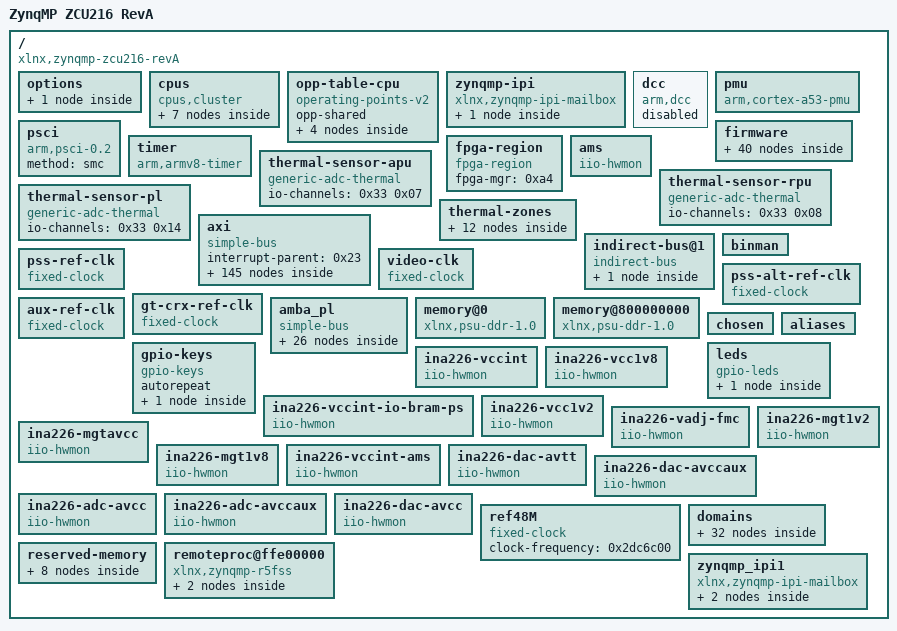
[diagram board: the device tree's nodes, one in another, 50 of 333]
/dts-v1/;

/ {
	compatible = "xlnx,zynqmp-zcu216-revA\0xlnx,zynqmp-zcu216\0xlnx,zynqmp\0ZynqMP ZCU216 RevA\0ZynqMP ZCU216 RevA\0ZynqMP ZCU216 RevA\0ZynqMP ZCU216 RevA\0ZynqMP ZCU216 RevA\0ZynqMP ZCU216 RevA\0ZynqMP ZCU216 RevA\0ZynqMP ZCU216 RevA\0ZynqMP ZCU216 RevA";
	#address-cells = <0x02>;
	#size-cells = <0x02>;
	model = "ZynqMP ZCU216 RevA";
	board = "zcu216";
	device_id = "xczu49dr";
	slrcount = <0x01>;
	family = "ZynqMP";
	speed_grade = "2";

	options {

		u-boot {
			compatible = "u-boot,config";
			bootscr-address = <0x00 0x20000000>;
		};
	};

	cpus {
		#address-cells = <0x01>;
		#size-cells = <0x00>;
		compatible = "cpus,cluster";
		#ranges-address-cells = <0x02>;
		#ranges-size-cells = <0x02>;
		phandle = <0xc7>;

		cpu@0 {
			#cooling-cells = <0x02>;
			compatible = "arm,cortex-a53";
			device_type = "cpu";
			enable-method = "psci";
			operating-points-v2 = <0x82>;
			reg = <0x00>;
			cpu-idle-states = <0x83>;
			next-level-cache = <0x84>;
			clocks = <0x85 0x0a>;
			xlnx,psu-ep = <0x01>;
			xlnx,pss-video-ref-clk-freq = <0x1fc9f08>;
			xlnx,ip-name = "psu_cortexa53";
			xlnx,cpu-1x-clk-freq-hz = <0x00>;
			xlnx,psu-silicon-version = <0x03>;
			cpu-frequency = <0x47865d45>;
			xlnx,cpu-clk-freq-hz = <0x47865d45>;
			xlnx,pss-gt-ref-clk-freq = <0x1fc9f08>;
			xlnx,pss-ref-clk-freq = <0x1fc9f08>;
			bus-handle = <0x01>;
			xlnx,pss-aux-ref-clk-freq = <0x1fc9f08>;
			xlnx,psu-device = "PS8a";
			xlnx,timestamp-clk-freq = <0x5f5dd19>;
			stamp-frequency = <0x5f5dd19>;
			xlnx,pss-alt-ref-clk-freq = <0x1fc9f08>;
			phandle = <0x9a>;
		};

		cpu@1 {
			#cooling-cells = <0x02>;
			compatible = "arm,cortex-a53";
			device_type = "cpu";
			enable-method = "psci";
			reg = <0x01>;
			operating-points-v2 = <0x82>;
			cpu-idle-states = <0x83>;
			next-level-cache = <0x84>;
			xlnx,timestamp-clk-freq = <0x5f5dd19>;
			xlnx,psu-ep = <0x01>;
			xlnx,pss-ref-clk-freq = <0x1fc9f08>;
			stamp-frequency = <0x5f5dd19>;
			xlnx,cpu-1x-clk-freq-hz = <0x00>;
			xlnx,ip-name = "psu_cortexa53";
			xlnx,psu-silicon-version = <0x03>;
			xlnx,psu-device = "PS8a";
			xlnx,cpu-clk-freq-hz = <0x47865d45>;
			bus-handle = <0x01>;
			cpu-frequency = <0x47865d45>;
			phandle = <0x9b>;
		};

		cpu@2 {
			#cooling-cells = <0x02>;
			compatible = "arm,cortex-a53";
			device_type = "cpu";
			enable-method = "psci";
			reg = <0x02>;
			operating-points-v2 = <0x82>;
			cpu-idle-states = <0x83>;
			next-level-cache = <0x84>;
			xlnx,timestamp-clk-freq = <0x5f5dd19>;
			xlnx,psu-ep = <0x01>;
			xlnx,pss-ref-clk-freq = <0x1fc9f08>;
			stamp-frequency = <0x5f5dd19>;
			xlnx,cpu-1x-clk-freq-hz = <0x00>;
			xlnx,ip-name = "psu_cortexa53";
			xlnx,psu-silicon-version = <0x03>;
			xlnx,psu-device = "PS8a";
			xlnx,cpu-clk-freq-hz = <0x47865d45>;
			bus-handle = <0x01>;
			cpu-frequency = <0x47865d45>;
			phandle = <0x9c>;
		};

		cpu@3 {
			#cooling-cells = <0x02>;
			compatible = "arm,cortex-a53";
			device_type = "cpu";
			enable-method = "psci";
			reg = <0x03>;
			operating-points-v2 = <0x82>;
			cpu-idle-states = <0x83>;
			next-level-cache = <0x84>;
			xlnx,timestamp-clk-freq = <0x5f5dd19>;
			xlnx,psu-ep = <0x01>;
			xlnx,pss-ref-clk-freq = <0x1fc9f08>;
			stamp-frequency = <0x5f5dd19>;
			xlnx,cpu-1x-clk-freq-hz = <0x00>;
			xlnx,ip-name = "psu_cortexa53";
			xlnx,psu-silicon-version = <0x03>;
			xlnx,psu-device = "PS8a";
			xlnx,cpu-clk-freq-hz = <0x47865d45>;
			bus-handle = <0x01>;
			cpu-frequency = <0x47865d45>;
			phandle = <0x9d>;
		};

		l2-cache {
			compatible = "cache";
			cache-level = <0x02>;
			cache-unified;
			phandle = <0x84>;
		};

		idle-states {
			entry-method = "psci";

			cpu-sleep-0 {
				compatible = "arm,idle-state";
				arm,psci-suspend-param = <0x40000000>;
				local-timer-stop;
				entry-latency-us = <0x12c>;
				exit-latency-us = <0x258>;
				min-residency-us = <0x2710>;
				phandle = <0x83>;
			};
		};
	};

	opp-table-cpu {
		compatible = "operating-points-v2";
		opp-shared;
		phandle = <0x82>;

		opp-1200000000 {
			opp-hz = <0x00 0x47868c00>;
			clock-latency-ns = <0x7a120>;
			opp-microvolt = <0xf4240>;
		};

		opp-600000000 {
			opp-hz = <0x00 0x23c34600>;
			clock-latency-ns = <0x7a120>;
			opp-microvolt = <0xf4240>;
		};

		opp-400000000 {
			opp-hz = <0x00 0x17d78400>;
			clock-latency-ns = <0x7a120>;
			opp-microvolt = <0xf4240>;
		};

		opp-300000000 {
			opp-hz = <0x00 0x11e1a300>;
			clock-latency-ns = <0x7a120>;
			opp-microvolt = <0xf4240>;
		};
	};

	zynqmp-ipi {
		bootph-all;
		compatible = "xlnx,zynqmp-ipi-mailbox";
		interrupt-parent = <0x23>;
		interrupts = <0x00 0x23 0x04>;
		xlnx,ipi-id = <0x00>;
		#address-cells = <0x02>;
		#size-cells = <0x02>;
		ranges;
		phandle = <0xce>;

		mailbox@ff9905c0 {
			bootph-all;
			compatible = "xlnx,zynqmp-ipi-dest-mailbox";
			reg = <0x00 0xff9905c0 0x00 0x20 0x00 0xff9905e0 0x00 0x20 0x00 0xff990e80 0x00 0x20 0x00 0xff990ea0 0x00 0x20>;
			reg-names = "local_request_region\0local_response_region\0remote_request_region\0remote_response_region";
			#mbox-cells = <0x01>;
			xlnx,ipi-id = <0x04>;
			phandle = <0x9e>;
		};
	};

	dcc {
		compatible = "arm,dcc";
		status = "disabled";
		bootph-all;
		phandle = <0xcf>;
	};

	pmu {
		compatible = "arm,cortex-a53-pmu";
		interrupt-parent = <0x23>;
		interrupts = <0x00 0x8f 0x04 0x00 0x90 0x04 0x00 0x91 0x04 0x00 0x92 0x04>;
		interrupt-affinity = <0x9a 0x9b 0x9c 0x9d>;
	};

	psci {
		compatible = "arm,psci-0.2";
		method = "smc";
	};

	firmware {

		zynqmp-firmware {
			compatible = "xlnx,zynqmp-firmware";
			#power-domain-cells = <0x01>;
			method = "smc";
			bootph-all;
			phandle = <0x8e>;

			power-management {
				bootph-all;
				compatible = "xlnx,zynqmp-power";
				interrupt-parent = <0x23>;
				interrupts = <0x00 0x23 0x04>;
				mboxes = <0x9e 0x00 0x9e 0x01>;
				mbox-names = "tx\0rx";
				phandle = <0xd0>;
			};

			soc-nvmem {
				compatible = "xlnx,zynqmp-nvmem-fw";

				nvmem-layout {
					compatible = "fixed-layout";
					#address-cells = <0x01>;
					#size-cells = <0x01>;

					soc-revision@0 {
						reg = <0x00 0x04>;
						phandle = <0xd1>;
					};

					efuse-dna@c {
						reg = <0x0c 0x0c>;
						phandle = <0xd2>;
					};

					efuse-usr0@20 {
						reg = <0x20 0x04>;
						phandle = <0xd3>;
					};

					efuse-usr1@24 {
						reg = <0x24 0x04>;
						phandle = <0xd4>;
					};

					efuse-usr2@28 {
						reg = <0x28 0x04>;
						phandle = <0xd5>;
					};

					efuse-usr3@2c {
						reg = <0x2c 0x04>;
						phandle = <0xd6>;
					};

					efuse-usr4@30 {
						reg = <0x30 0x04>;
						phandle = <0xd7>;
					};

					efuse-usr5@34 {
						reg = <0x34 0x04>;
						phandle = <0xd8>;
					};

					efuse-usr6@38 {
						reg = <0x38 0x04>;
						phandle = <0xd9>;
					};

					efuse-usr7@3c {
						reg = <0x3c 0x04>;
						phandle = <0xda>;
					};

					efuse-miscusr@40 {
						reg = <0x40 0x04>;
						phandle = <0xdb>;
					};

					efuse-chash@50 {
						reg = <0x50 0x04>;
						phandle = <0xdc>;
					};

					efuse-pufmisc@54 {
						reg = <0x54 0x04>;
						phandle = <0xdd>;
					};

					efuse-sec@58 {
						reg = <0x58 0x04>;
						phandle = <0xde>;
					};

					efuse-spkid@5c {
						reg = <0x5c 0x04>;
						phandle = <0xdf>;
					};

					efuse-aeskey@60 {
						reg = <0x60 0x20>;
						phandle = <0xe0>;
					};

					efuse-ppk0hash@a0 {
						reg = <0xa0 0x30>;
						phandle = <0xe1>;
					};

					efuse-ppk1hash@d0 {
						reg = <0xd0 0x30>;
						phandle = <0xe2>;
					};

					efuse-pufuser@100 {
						reg = <0x100 0x7f>;
						phandle = <0xe3>;
					};
				};
			};

			pcap {
				compatible = "xlnx,zynqmp-pcap-fpga";
				phandle = <0xa4>;
			};

			reset-controller {
				compatible = "xlnx,zynqmp-reset";
				#reset-cells = <0x01>;
				status = "okay";
				phandle = <0x03>;
			};

			pinctrl {
				compatible = "xlnx,zynqmp-pinctrl";
				status = "okay";
				phandle = <0x04>;

				i2c0-default {
					phandle = <0xab>;

					mux {
						groups = "i2c0_3_grp";
						function = "i2c0";
					};

					conf {
						groups = "i2c0_3_grp";
						bias-pull-up;
						slew-rate = <0x01>;
						power-source = <0x01>;
					};
				};

				i2c0-gpio-grp {
					phandle = <0xac>;

					mux {
						groups = "gpio0_14_grp\0gpio0_15_grp";
						function = "gpio0";
					};

					conf {
						groups = "gpio0_14_grp\0gpio0_15_grp";
						slew-rate = <0x01>;
						power-source = <0x01>;
					};
				};

				i2c1-default {
					phandle = <0xad>;

					mux {
						groups = "i2c1_4_grp";
						function = "i2c1";
					};

					conf {
						groups = "i2c1_4_grp";
						bias-pull-up;
						slew-rate = <0x01>;
						power-source = <0x01>;
					};
				};

				i2c1-gpio-grp {
					phandle = <0xae>;

					mux {
						groups = "gpio0_16_grp\0gpio0_17_grp";
						function = "gpio0";
					};

					conf {
						groups = "gpio0_16_grp\0gpio0_17_grp";
						slew-rate = <0x01>;
						power-source = <0x01>;
					};
				};
			};

			gpio {
				compatible = "xlnx,zynqmp-gpio-modepin";
				gpio-controller;
				#gpio-cells = <0x02>;
				phandle = <0xb3>;
			};

			clock-controller {
				bootph-all;
				#clock-cells = <0x01>;
				compatible = "xlnx,zynqmp-clk";
				clocks = <0x9f 0xa0 0xa1 0xa2 0xa3>;
				clock-names = "pss_ref_clk\0video_clk\0pss_alt_ref_clk\0aux_ref_clk\0gt_crx_ref_clk";
				phandle = <0x85>;
			};
		};
	};

	timer {
		compatible = "arm,armv8-timer";
		interrupt-parent = <0x23>;
		interrupts = <0x01 0x0d 0xf08 0x01 0x0e 0xf08 0x01 0x0b 0xf08 0x01 0x0a 0xf08>;
	};

	fpga-region {
		compatible = "fpga-region";
		fpga-mgr = <0xa4>;
		#address-cells = <0x02>;
		#size-cells = <0x02>;
		ranges;
		phandle = <0xe4>;
	};

	ams {
		compatible = "iio-hwmon";
		io-channels = <0x33 0x00 0x33 0x01 0x33 0x02 0x33 0x03 0x33 0x04 0x33 0x05 0x33 0x06 0x33 0x07 0x33 0x08 0x33 0x09 0x33 0x0a 0x33 0x0b 0x33 0x0c 0x33 0x0d 0x33 0x0e 0x33 0x0f 0x33 0x10 0x33 0x11 0x33 0x12 0x33 0x13 0x33 0x14 0x33 0x15 0x33 0x16 0x33 0x17 0x33 0x18 0x33 0x19 0x33 0x1a 0x33 0x1b 0x33 0x1c 0x33 0x1d>;
	};

	thermal-sensor-apu {
		compatible = "generic-adc-thermal";
		#thermal-sensor-cells = <0x00>;
		io-channels = <0x33 0x07>;
		io-channel-names = "sensor-channel";
		phandle = <0xa5>;
	};

	thermal-sensor-rpu {
		compatible = "generic-adc-thermal";
		#thermal-sensor-cells = <0x00>;
		io-channels = <0x33 0x08>;
		io-channel-names = "sensor-channel";
		phandle = <0xa7>;
	};

	thermal-sensor-pl {
		compatible = "generic-adc-thermal";
		#thermal-sensor-cells = <0x00>;
		io-channels = <0x33 0x14>;
		io-channel-names = "sensor-channel";
		phandle = <0xa8>;
	};

	thermal-zones {

		apu-thermal {
			polling-delay-passive = <0x3e8>;
			polling-delay = <0x1388>;
			thermal-sensors = <0xa5>;

			trips {

				passive {
					temperature = <0x16b48>;
					hysteresis = <0xdac>;
					type = "passive";
					phandle = <0xa6>;
				};

				critical {
					temperature = <0x178f4>;
					hysteresis = <0xdac>;
					type = "critical";
					phandle = <0xe5>;
				};
			};

			cooling-maps {

				map {
					trip = <0xa6>;
					cooling-device = <0x9a 0xffffffff 0xffffffff 0x9b 0xffffffff 0xffffffff 0x9c 0xffffffff 0xffffffff 0x9d 0xffffffff 0xffffffff>;
				};
			};
		};

		rpu-thermal {
			polling-delay = <0x2710>;
			thermal-sensors = <0xa7>;

			trips {

				critical {
					temperature = <0x178f4>;
					hysteresis = <0xdac>;
					type = "critical";
				};
			};
		};

		pl-thermal {
			polling-delay = <0x2710>;
			thermal-sensors = <0xa8>;

			trips {

				critical {
					temperature = <0x178f4>;
					hysteresis = <0xdac>;
					type = "critical";
				};
			};
		};
	};

	axi {
		compatible = "simple-bus";
		bootph-all;
		#address-cells = <0x02>;
		#size-cells = <0x02>;
		ranges;
		interrupt-parent = <0x23>;
		phandle = <0x01>;

		can@ff060000 {
			compatible = "xlnx,zynq-can-1.0";
			status = "disabled";
			clock-names = "can_clk\0pclk";
			reg = <0x00 0xff060000 0x00 0x1000>;
			interrupts = <0x00 0x17 0x04>;
			interrupt-parent = <0x23>;
			tx-fifo-depth = <0x40>;
			rx-fifo-depth = <0x40>;
			resets = <0x03 0x28>;
			power-domains = <0x8e 0x2f>;
			clocks = <0x85 0x3f 0x85 0x1f>;
			phandle = <0xe6>;
		};

		can@ff070000 {
			compatible = "xlnx,zynq-can-1.0";
			status = "disabled";
			clock-names = "can_clk\0pclk";
			reg = <0x00 0xff070000 0x00 0x1000>;
			interrupts = <0x00 0x18 0x04>;
			interrupt-parent = <0x23>;
			tx-fifo-depth = <0x40>;
			rx-fifo-depth = <0x40>;
			resets = <0x03 0x29>;
			power-domains = <0x8e 0x30>;
			clocks = <0x85 0x40 0x85 0x1f>;
			phandle = <0xe7>;
		};

		cci@fd6e0000 {
			compatible = "arm,cci-400";
			status = "disabled";
			reg = <0x00 0xfd6e0000 0x00 0x9000>;
			ranges = <0x00 0x00 0xfd6e0000 0x10000>;
			#address-cells = <0x01>;
			#size-cells = <0x01>;
			phandle = <0xe8>;

			pmu@9000 {
				compatible = "arm,cci-400-pmu,r1";
				reg = <0x9000 0x5000>;
				interrupt-parent = <0x23>;
				interrupts = <0x00 0x7b 0x04 0x00 0x7b 0x04 0x00 0x7b 0x04 0x00 0x7b 0x04 0x00 0x7b 0x04>;
			};
		};

		debug@fec10000 {
			compatible = "arm,coresight-cpu-debug\0arm,primecell";
			reg = <0x00 0xfec10000 0x00 0x1000>;
			clock-names = "apb_pclk";
			cpu = <0x9a>;
			clocks = <0x85 0x0c>;
			phandle = <0xe9>;
		};

		debug@fed10000 {
			compatible = "arm,coresight-cpu-debug\0arm,primecell";
			reg = <0x00 0xfed10000 0x00 0x1000>;
			clock-names = "apb_pclk";
			cpu = <0x9b>;
			clocks = <0x85 0x0c>;
			phandle = <0xea>;
		};

		debug@fee10000 {
			compatible = "arm,coresight-cpu-debug\0arm,primecell";
			reg = <0x00 0xfee10000 0x00 0x1000>;
			clock-names = "apb_pclk";
			cpu = <0x9c>;
			clocks = <0x85 0x0c>;
			phandle = <0xeb>;
		};

		debug@fef10000 {
			compatible = "arm,coresight-cpu-debug\0arm,primecell";
			reg = <0x00 0xfef10000 0x00 0x1000>;
			clock-names = "apb_pclk";
			cpu = <0x9d>;
			clocks = <0x85 0x0c>;
			phandle = <0xec>;
		};

		dma-controller@fd500000 {
			status = "okay";
			compatible = "xlnx,zynqmp-dma-1.0";
			reg = <0x00 0xfd500000 0x00 0x1000>;
			interrupt-parent = <0x23>;
			interrupts = <0x00 0x7c 0x04>;
			clock-names = "clk_main\0clk_apb";
			#dma-cells = <0x01>;
			xlnx,bus-width = <0x80>;
			power-domains = <0x8e 0x2a>;
			clocks = <0x85 0x13 0x85 0x1f>;
			xlnx,ip-name = "psu_gdma";
			xlnx,dma-mode = <0x00>;
			xlnx,dma-type = <0x00>;
			phandle = <0x51>;
		};

		dma-controller@fd510000 {
			status = "okay";
			compatible = "xlnx,zynqmp-dma-1.0";
			reg = <0x00 0xfd510000 0x00 0x1000>;
			interrupt-parent = <0x23>;
			interrupts = <0x00 0x7d 0x04>;
			clock-names = "clk_main\0clk_apb";
			#dma-cells = <0x01>;
			xlnx,bus-width = <0x80>;
			power-domains = <0x8e 0x2a>;
			clocks = <0x85 0x13 0x85 0x1f>;
			xlnx,ip-name = "psu_gdma";
			xlnx,dma-mode = <0x00>;
			xlnx,dma-type = <0x00>;
			phandle = <0x52>;
		};

		dma-controller@fd520000 {
			status = "okay";
			compatible = "xlnx,zynqmp-dma-1.0";
			reg = <0x00 0xfd520000 0x00 0x1000>;
			interrupt-parent = <0x23>;
			interrupts = <0x00 0x7e 0x04>;
			clock-names = "clk_main\0clk_apb";
			#dma-cells = <0x01>;
			xlnx,bus-width = <0x80>;
			power-domains = <0x8e 0x2a>;
			clocks = <0x85 0x13 0x85 0x1f>;
			xlnx,ip-name = "psu_gdma";
			xlnx,dma-mode = <0x00>;
			xlnx,dma-type = <0x00>;
			phandle = <0x53>;
		};

		dma-controller@fd530000 {
			status = "okay";
			compatible = "xlnx,zynqmp-dma-1.0";
			reg = <0x00 0xfd530000 0x00 0x1000>;
			interrupt-parent = <0x23>;
			interrupts = <0x00 0x7f 0x04>;
			clock-names = "clk_main\0clk_apb";
			#dma-cells = <0x01>;
			xlnx,bus-width = <0x80>;
			power-domains = <0x8e 0x2a>;
			clocks = <0x85 0x13 0x85 0x1f>;
			xlnx,ip-name = "psu_gdma";
			xlnx,dma-mode = <0x00>;
			xlnx,dma-type = <0x00>;
			phandle = <0x54>;
		};

		dma-controller@fd540000 {
			status = "okay";
			compatible = "xlnx,zynqmp-dma-1.0";
			reg = <0x00 0xfd540000 0x00 0x1000>;
			interrupt-parent = <0x23>;
			interrupts = <0x00 0x80 0x04>;
			clock-names = "clk_main\0clk_apb";
			#dma-cells = <0x01>;
			xlnx,bus-width = <0x80>;
			power-domains = <0x8e 0x2a>;
			clocks = <0x85 0x13 0x85 0x1f>;
			xlnx,ip-name = "psu_gdma";
			xlnx,dma-mode = <0x00>;
			xlnx,dma-type = <0x00>;
			phandle = <0x55>;
		};

		dma-controller@fd550000 {
			status = "okay";
			compatible = "xlnx,zynqmp-dma-1.0";
			reg = <0x00 0xfd550000 0x00 0x1000>;
			interrupt-parent = <0x23>;
			interrupts = <0x00 0x81 0x04>;
			clock-names = "clk_main\0clk_apb";
			#dma-cells = <0x01>;
			xlnx,bus-width = <0x80>;
			power-domains = <0x8e 0x2a>;
			clocks = <0x85 0x13 0x85 0x1f>;
			xlnx,ip-name = "psu_gdma";
			xlnx,dma-mode = <0x00>;
			xlnx,dma-type = <0x00>;
			phandle = <0x56>;
		};

		dma-controller@fd560000 {
			status = "okay";
			compatible = "xlnx,zynqmp-dma-1.0";
			reg = <0x00 0xfd560000 0x00 0x1000>;
			interrupt-parent = <0x23>;
			interrupts = <0x00 0x82 0x04>;
			clock-names = "clk_main\0clk_apb";
			#dma-cells = <0x01>;
			xlnx,bus-width = <0x80>;
			power-domains = <0x8e 0x2a>;
			clocks = <0x85 0x13 0x85 0x1f>;
			xlnx,ip-name = "psu_gdma";
			xlnx,dma-mode = <0x00>;
			xlnx,dma-type = <0x00>;
			phandle = <0x57>;
		};

		dma-controller@fd570000 {
			status = "okay";
			compatible = "xlnx,zynqmp-dma-1.0";
			reg = <0x00 0xfd570000 0x00 0x1000>;
			interrupt-parent = <0x23>;
			interrupts = <0x00 0x83 0x04>;
			clock-names = "clk_main\0clk_apb";
			#dma-cells = <0x01>;
			xlnx,bus-width = <0x80>;
			power-domains = <0x8e 0x2a>;
			clocks = <0x85 0x13 0x85 0x1f>;
			xlnx,ip-name = "psu_gdma";
			xlnx,dma-mode = <0x00>;
			xlnx,dma-type = <0x00>;
			phandle = <0x58>;
		};

		gpu@fd4b0000 {
			status = "disabled";
			compatible = "xlnx,zynqmp-mali\0arm,mali-400";
			reg = <0x00 0xfd4b0000 0x00 0x10000>;
			interrupt-parent = <0x23>;
			interrupts = <0x00 0x84 0x04 0x00 0x84 0x04 0x00 0x84 0x04 0x00 0x84 0x04 0x00 0x84 0x04 0x00 0x84 0x04>;
			interrupt-names = "gp\0gpmmu\0pp0\0ppmmu0\0pp1\0ppmmu1";
			clock-names = "bus\0core";
			power-domains = <0x8e 0x3a>;
			clocks = <0x85 0x18 0x85 0x19>;
			phandle = <0xed>;
		};

		dma-controller@ffa80000 {
			status = "okay";
			compatible = "xlnx,zynqmp-dma-1.0";
			reg = <0x00 0xffa80000 0x00 0x1000>;
			interrupt-parent = <0x23>;
			interrupts = <0x00 0x4d 0x04>;
			clock-names = "clk_main\0clk_apb";
			#dma-cells = <0x01>;
			xlnx,bus-width = <0x40>;
			power-domains = <0x8e 0x2b>;
			clocks = <0x85 0x44 0x85 0x1f>;
			xlnx,is-cache-coherent = <0x00>;
			xlnx,ip-name = "psu_adma";
			xlnx,dma-mode = <0x01>;
			xlnx,dma-type = <0x01>;
			phandle = <0x24>;
		};

		dma-controller@ffa90000 {
			status = "okay";
			compatible = "xlnx,zynqmp-dma-1.0";
			reg = <0x00 0xffa90000 0x00 0x1000>;
			interrupt-parent = <0x23>;
			interrupts = <0x00 0x4e 0x04>;
			clock-names = "clk_main\0clk_apb";
			#dma-cells = <0x01>;
			xlnx,bus-width = <0x40>;
			power-domains = <0x8e 0x2b>;
			clocks = <0x85 0x44 0x85 0x1f>;
			xlnx,is-cache-coherent = <0x00>;
			xlnx,ip-name = "psu_adma";
			xlnx,dma-mode = <0x01>;
			xlnx,dma-type = <0x01>;
			phandle = <0x25>;
		};

		dma-controller@ffaa0000 {
			status = "okay";
			compatible = "xlnx,zynqmp-dma-1.0";
			reg = <0x00 0xffaa0000 0x00 0x1000>;
			interrupt-parent = <0x23>;
			interrupts = <0x00 0x4f 0x04>;
			clock-names = "clk_main\0clk_apb";
			#dma-cells = <0x01>;
			xlnx,bus-width = <0x40>;
			power-domains = <0x8e 0x2b>;
			clocks = <0x85 0x44 0x85 0x1f>;
			xlnx,is-cache-coherent = <0x00>;
			xlnx,ip-name = "psu_adma";
			xlnx,dma-mode = <0x01>;
			xlnx,dma-type = <0x01>;
			phandle = <0x26>;
		};

		dma-controller@ffab0000 {
			status = "okay";
			compatible = "xlnx,zynqmp-dma-1.0";
			reg = <0x00 0xffab0000 0x00 0x1000>;
			interrupt-parent = <0x23>;
			interrupts = <0x00 0x50 0x04>;
			clock-names = "clk_main\0clk_apb";
			#dma-cells = <0x01>;
			xlnx,bus-width = <0x40>;
			power-domains = <0x8e 0x2b>;
			clocks = <0x85 0x44 0x85 0x1f>;
			xlnx,is-cache-coherent = <0x00>;
			xlnx,ip-name = "psu_adma";
			xlnx,dma-mode = <0x01>;
			xlnx,dma-type = <0x01>;
			phandle = <0x27>;
		};

		dma-controller@ffac0000 {
			status = "okay";
			compatible = "xlnx,zynqmp-dma-1.0";
			reg = <0x00 0xffac0000 0x00 0x1000>;
			interrupt-parent = <0x23>;
			interrupts = <0x00 0x51 0x04>;
			clock-names = "clk_main\0clk_apb";
			#dma-cells = <0x01>;
			xlnx,bus-width = <0x40>;
			power-domains = <0x8e 0x2b>;
			clocks = <0x85 0x44 0x85 0x1f>;
			xlnx,is-cache-coherent = <0x00>;
			xlnx,ip-name = "psu_adma";
			xlnx,dma-mode = <0x01>;
			xlnx,dma-type = <0x01>;
			phandle = <0x28>;
		};

		dma-controller@ffad0000 {
			status = "okay";
			compatible = "xlnx,zynqmp-dma-1.0";
			reg = <0x00 0xffad0000 0x00 0x1000>;
			interrupt-parent = <0x23>;
			interrupts = <0x00 0x52 0x04>;
			clock-names = "clk_main\0clk_apb";
			#dma-cells = <0x01>;
			xlnx,bus-width = <0x40>;
			power-domains = <0x8e 0x2b>;
			clocks = <0x85 0x44 0x85 0x1f>;
			xlnx,is-cache-coherent = <0x00>;
			xlnx,ip-name = "psu_adma";
			xlnx,dma-mode = <0x01>;
			xlnx,dma-type = <0x01>;
			phandle = <0x29>;
		};

		dma-controller@ffae0000 {
			status = "okay";
			compatible = "xlnx,zynqmp-dma-1.0";
			reg = <0x00 0xffae0000 0x00 0x1000>;
			interrupt-parent = <0x23>;
			interrupts = <0x00 0x53 0x04>;
			clock-names = "clk_main\0clk_apb";
			#dma-cells = <0x01>;
			xlnx,bus-width = <0x40>;
			power-domains = <0x8e 0x2b>;
			clocks = <0x85 0x44 0x85 0x1f>;
			xlnx,is-cache-coherent = <0x00>;
			xlnx,ip-name = "psu_adma";
			xlnx,dma-mode = <0x01>;
			xlnx,dma-type = <0x01>;
			phandle = <0x2a>;
		};

		dma-controller@ffaf0000 {
			status = "okay";
			compatible = "xlnx,zynqmp-dma-1.0";
			reg = <0x00 0xffaf0000 0x00 0x1000>;
			interrupt-parent = <0x23>;
			interrupts = <0x00 0x54 0x04>;
			clock-names = "clk_main\0clk_apb";
			#dma-cells = <0x01>;
			xlnx,bus-width = <0x40>;
			power-domains = <0x8e 0x2b>;
			clocks = <0x85 0x44 0x85 0x1f>;
			xlnx,is-cache-coherent = <0x00>;
			xlnx,ip-name = "psu_adma";
			xlnx,dma-mode = <0x01>;
			xlnx,dma-type = <0x01>;
			phandle = <0x2b>;
		};

		memory-controller@fd070000 {
			compatible = "xlnx,zynqmp-ddrc-2.40a";
			reg = <0x00 0xfd070000 0x00 0x30000>;
			interrupt-parent = <0x23>;
			interrupts = <0x00 0x70 0x04>;
			xlnx,bank-addr-bits = <0x02>;
			xlnx,ddrc-parity = <0x00>;
			xlnx,addr-mapping = <0x00>;
			xlnx,has-ecc = <0x00>;
			xlnx,ddr-freq = <0x3e95917d>;
			xlnx,row-addr-bits = <0x10>;
			xlnx,ddrc-low-power-auto-self-refresh = <0x00>;
			xlnx,ip-name = "psu_ddrc";
			xlnx,ddrc-2nd-clock = <0x00>;
			xlnx,brc-mapping = <0x00>;
			xlnx,ddrc-address-copy = <0x00>;
			xlnx,ddrc-data-mask-and-dbi = <0x07>;
			xlnx,ddrc-fine-granularity-refresh-mode = <0x00>;
			xlnx,ddrc-memory-type = <0x04>;
			xlnx,col-addr-bits = <0x0a>;
			xlnx,ddrc-self-refresh-abort = <0x00>;
			xlnx,ddrc-max-operating-temparature = <0x00>;
			status = "okay";
			xlnx,ddrc-address-mirroring = <0x00>;
			xlnx,ddrc-clk-freq-hz = <0x1f4ac8be>;
			xlnx,qos-enable = <0x00>;
			xlnx,ddrc-temp-controlled-refresh = <0x00>;
			xlnx,bg-addr-bits = <0x01>;
			xlnx,ddrc-power-down-enable = <0x00>;
			xlnx,video-buf-size = <0x00>;
			xlnx,ddrc-memory-address-map = <0x00>;
			xlnx,dddrc-ecc = <0x00>;
			xlnx,ddrc-clock-stop = <0x00>;
			xlnx,ddrc-dynamic-ddr-config-enabled = <0x01>;
			phandle = <0x49>;
		};

		nand-controller@ff100000 {
			compatible = "xlnx,zynqmp-nand-controller\0arasan,nfc-v3p10";
			status = "disabled";
			reg = <0x00 0xff100000 0x00 0x1000>;
			clock-names = "controller\0bus";
			interrupt-parent = <0x23>;
			interrupts = <0x00 0x0e 0x04>;
			#address-cells = <0x01>;
			#size-cells = <0x00>;
			power-domains = <0x8e 0x2c>;
			clocks = <0x85 0x3c 0x85 0x1f>;
			phandle = <0xee>;
		};

		ethernet@ff0b0000 {
			compatible = "xlnx,zynqmp-gem\0cdns,gem";
			status = "disabled";
			interrupt-parent = <0x23>;
			interrupts = <0x00 0x39 0x04 0x00 0x39 0x04>;
			reg = <0x00 0xff0b0000 0x00 0x1000>;
			clock-names = "pclk\0hclk\0tx_clk\0rx_clk\0tsu_clk";
			power-domains = <0x8e 0x1d>;
			resets = <0x03 0x1d>;
			reset-names = "gem0_rst";
			clocks = <0x85 0x1f 0x85 0x68 0x85 0x2d 0x85 0x31 0x85 0x2c>;
			assigned-clocks = <0x85 0x2c>;
			phandle = <0xef>;
		};

		ethernet@ff0c0000 {
			compatible = "xlnx,zynqmp-gem\0cdns,gem";
			status = "disabled";
			interrupt-parent = <0x23>;
			interrupts = <0x00 0x3b 0x04 0x00 0x3b 0x04>;
			reg = <0x00 0xff0c0000 0x00 0x1000>;
			clock-names = "pclk\0hclk\0tx_clk\0rx_clk\0tsu_clk";
			power-domains = <0x8e 0x1e>;
			resets = <0x03 0x1e>;
			reset-names = "gem1_rst";
			clocks = <0x85 0x1f 0x85 0x69 0x85 0x2e 0x85 0x32 0x85 0x2c>;
			assigned-clocks = <0x85 0x2c>;
			phandle = <0xf0>;
		};

		ethernet@ff0d0000 {
			compatible = "xlnx,zynqmp-gem\0cdns,gem";
			status = "disabled";
			interrupt-parent = <0x23>;
			interrupts = <0x00 0x3d 0x04 0x00 0x3d 0x04>;
			reg = <0x00 0xff0d0000 0x00 0x1000>;
			clock-names = "pclk\0hclk\0tx_clk\0rx_clk\0tsu_clk";
			power-domains = <0x8e 0x1f>;
			resets = <0x03 0x1f>;
			reset-names = "gem2_rst";
			clocks = <0x85 0x1f 0x85 0x6a 0x85 0x2f 0x85 0x33 0x85 0x2c>;
			assigned-clocks = <0x85 0x2c>;
			phandle = <0xf1>;
		};

		ethernet@ff0e0000 {
			compatible = "xlnx,zynqmp-gem\0cdns,gem";
			status = "okay";
			interrupt-parent = <0x23>;
			interrupts = <0x00 0x3f 0x04 0x00 0x3f 0x04>;
			reg = <0x00 0xff0e0000 0x00 0x1000>;
			clock-names = "pclk\0hclk\0tx_clk\0rx_clk\0tsu_clk";
			power-domains = <0x8e 0x20>;
			resets = <0x03 0x20>;
			reset-names = "gem3_rst";
			clocks = <0x85 0x1f 0x85 0x6b 0x85 0x30 0x85 0x34 0x85 0x2c>;
			assigned-clocks = <0x85 0x2c>;
			xlnx,is-cache-coherent = <0x00>;
			xlnx,has-mdio = <0x2faf080>;
			xlnx,gem-board-interface = "custom";
			phy-mode = "rgmii-id";
			xlnx,tz-nonsecure = <0x01>;
			xlnx,enet-slcr-1000mbps-div0 = <0x0c>;
			xlnx,enet-slcr-10mbps-div0 = <0x3c>;
			xlnx,enet-slcr-1000mbps-div1 = <0x01>;
			xlnx,enet-slcr-10mbps-div1 = <0x0a>;
			xlnx,enet-tsu-clk-freq-hz = <0xee6a8ba>;
			xlnx,ip-name = "psu_ethernet";
			xlnx,eth-mode = <0x01>;
			xlnx,enet-reset = <0x2faf080>;
			xlnx,enet-clk-freq-hz = <0x773545d>;
			xlnx,enet-slcr-100mbps-div0 = <0x3c>;
			xlnx,ptp-enet-clock = <0x00>;
			xlnx,enet-slcr-100mbps-div1 = <0x01>;
			phy-handle = <0xa9>;
			phandle = <0x4b>;

			mdio {
				#address-cells = <0x01>;
				#size-cells = <0x00>;
				phandle = <0xf2>;

				ethernet-phy@c {
					#phy-cells = <0x01>;
					compatible = "ethernet-phy-id2000.a231";
					reg = <0x0c>;
					ti,rx-internal-delay = <0x08>;
					ti,tx-internal-delay = <0x0a>;
					ti,fifo-depth = <0x01>;
					ti,dp83867-rxctrl-strap-quirk;
					reset-gpios = <0xaa 0x06 0x01>;
					phandle = <0xa9>;
				};
			};
		};

		gpio@ff0a0000 {
			compatible = "xlnx,zynqmp-gpio-1.0";
			status = "okay";
			#gpio-cells = <0x02>;
			gpio-controller;
			interrupt-parent = <0x23>;
			interrupts = <0x00 0x10 0x04>;
			interrupt-controller;
			#interrupt-cells = <0x02>;
			reg = <0x00 0xff0a0000 0x00 0x1000>;
			power-domains = <0x8e 0x2e>;
			clocks = <0x85 0x1f>;
			xlnx,gpio-board-interface = "custom";
			xlnx,mio-gpio-mask = <0x5600>;
			gpio-mask-high = <0x00>;
			xlnx,emio-gpio-width = <0x20>;
			xlnx,ip-name = "psu_gpio";
			gpio-mask-low = <0x5600>;
			emio-gpio-width = <0x20>;
			gpio-line-names = "QSPI_LWR_CLK\0QSPI_LWR_DQ1\0QSPI_LWR_DQ2\0QSPI_LWR_DQ3\0QSPI_LWR_DQ0\0QSPI_LWR_CS_B\0\0QSPI_UPR_CS_B\0QSPI_UPR_DQ0\0QSPI_UPR_DQ1\0QSPI_UPR_DQ2\0QSPI_UPR_DQ3\0QSPI_UPR_CLK\0PS_GPIO2\0I2C0_SCL\0I2C0_SDA\0I2C1_SCL\0I2C1_SDA\0UART0_TXD\0UART0_RXD\0\0\0BUTTON\0LED\0\0\0PMU_INPUT\0\0\0\0\0\0PMU_GPO0\0PMU_GPO1\0PMU_GPO2\0PMU_GPO3\0PMU_GPO4\0PMU_GPO5\0PS_GPIO1\0SDIO_SEL\0SDIO_DIR_CMD\0SDIO_DIR_DAT0\0SDIO_DIR_DAT1\0\0\0SDIO_DETECT\0SDIO_DAT0\0SDIO_DAT1\0SDIO_DAT2\0SDIO_DAT3\0SDIO_CMD\0SDIO_CLK\0USB_CLK\0USB_DIR\0USB_DATA2\0USB_NXT\0USB_DATA0\0USB_DATA1\0USB_STP\0USB_DATA3\0USB_DATA4\0USB_DATA5\0USB_DATA6\0USB_DATA7\0ENET_TX_CLK\0ENET_TX_D0\0ENET_TX_D1\0ENET_TX_D2\0ENET_TX_D3\0ENET_TX_CTRL\0ENET_RX_CLK\0ENET_RX_D0\0ENET_RX_D1\0ENET_RX_D2\0ENET_RX_D3\0ENET_RX_CTRL\0ENET_MDC\0ENET_MDIO\0\0\0\0\0\0\0\0\0\0\0\0\0\0\0\0\0\0\0\0\0\0\0\0\0\0\0\0\0\0\0\0\0\0\0\0\0\0\0\0\0\0\0\0\0\0\0\0\0\0\0\0\0\0\0\0\0\0\0\0\0\0\0\0\0\0\0\0\0\0\0\0\0\0\0\0\0\0\0\0\0\0\0\0\0\0\0\0\0\0\0\0\0\0\0\0";
			phandle = <0x59>;
		};

		i2c@ff020000 {
			compatible = "cdns,i2c-r1p14";
			status = "okay";
			interrupt-parent = <0x23>;
			interrupts = <0x00 0x11 0x04>;
			clock-frequency = <0x61a80>;
			reg = <0x00 0xff020000 0x00 0x1000>;
			#address-cells = <0x01>;
			#size-cells = <0x00>;
			power-domains = <0x8e 0x25>;
			clocks = <0x85 0x3d>;
			xlnx,i2c-reset = <0x00>;
			xlnx,has-interrupt = <0x2faf080>;
			xlnx,clock-freq = <0x5f5dd19>;
			xlnx,i2c-clk-freq-hz = <0x5f5dd19>;
			xlnx,ip-name = "psu_i2c";
			xlnx,iic-board-interface = "custom";
			pinctrl-names = "default\0gpio";
			pinctrl-0 = <0xab>;
			pinctrl-1 = <0xac>;
			scl-gpios = <0x59 0x0e 0x06>;
			sda-gpios = <0x59 0x0f 0x06>;
			phandle = <0x5a>;

			gpio@20 {
				compatible = "ti,tca6416";
				reg = <0x20>;
				gpio-controller;
				#gpio-cells = <0x02>;
				gpio-line-names = "MAX6643_OT_B\0MAX6643_FANFAIL_B\0MIO26_PMU_INPUT_LS\0\0\0IIC_MUX_RESET_B\0GEM3_EXP_RESET_B\0MAX6643_FULL_SPEED\0FMCP_HSPC_PRSNT_M2C_B\0\0\0VCCINT_VRHOT_B\0\08A34001_EXP_RST_B\0IRPS5401_ALERT_B\0INA226_PMBUS_ALERT";
				phandle = <0xaa>;
			};

			i2c-mux@75 {
				compatible = "nxp,pca9544";
				#address-cells = <0x01>;
				#size-cells = <0x00>;
				reg = <0x75>;

				i2c@0 {
					#address-cells = <0x01>;
					#size-cells = <0x00>;
					reg = <0x00>;

					ina226@40 {
						compatible = "ti,ina226";
						#io-channel-cells = <0x01>;
						label = "ina226-vccint";
						reg = <0x40>;
						shunt-resistor = <0x1388>;
						phandle = <0xb9>;
					};

					ina226@41 {
						compatible = "ti,ina226";
						#io-channel-cells = <0x01>;
						label = "ina226-vccint-io-bram-ps";
						reg = <0x41>;
						shunt-resistor = <0x1388>;
						phandle = <0xba>;
					};

					ina226@42 {
						compatible = "ti,ina226";
						#io-channel-cells = <0x01>;
						label = "ina226-vcc1v8";
						reg = <0x42>;
						shunt-resistor = <0x7d0>;
						phandle = <0xbb>;
					};

					ina226@43 {
						compatible = "ti,ina226";
						#io-channel-cells = <0x01>;
						label = "ina226-vcc1v2";
						reg = <0x43>;
						shunt-resistor = <0x1388>;
						phandle = <0xbc>;
					};

					ina226@45 {
						compatible = "ti,ina226";
						#io-channel-cells = <0x01>;
						label = "ina226-vadj-fmc";
						reg = <0x45>;
						shunt-resistor = <0x1388>;
						phandle = <0xbd>;
					};

					ina226@46 {
						compatible = "ti,ina226";
						#io-channel-cells = <0x01>;
						label = "ina226-mgtavcc";
						reg = <0x46>;
						shunt-resistor = <0x7d0>;
						phandle = <0xbe>;
					};

					ina226@47 {
						compatible = "ti,ina226";
						#io-channel-cells = <0x01>;
						label = "ina226-mgt1v2";
						reg = <0x47>;
						shunt-resistor = <0x1388>;
						phandle = <0xbf>;
					};

					ina226@48 {
						compatible = "ti,ina226";
						#io-channel-cells = <0x01>;
						label = "ina226-mgt1v8";
						reg = <0x48>;
						shunt-resistor = <0x1388>;
						phandle = <0xc0>;
					};

					ina226@49 {
						compatible = "ti,ina226";
						#io-channel-cells = <0x01>;
						label = "ina226-vccint-ams";
						reg = <0x49>;
						shunt-resistor = <0x1388>;
						phandle = <0xc1>;
					};

					ina226@4a {
						compatible = "ti,ina226";
						#io-channel-cells = <0x01>;
						label = "ina226-dac-avtt";
						reg = <0x4a>;
						shunt-resistor = <0x1388>;
						phandle = <0xc2>;
					};

					ina226@4b {
						compatible = "ti,ina226";
						#io-channel-cells = <0x01>;
						label = "ina226-dac-avccaux";
						reg = <0x4b>;
						shunt-resistor = <0x1388>;
						phandle = <0xc3>;
					};

					ina226@4c {
						compatible = "ti,ina226";
						#io-channel-cells = <0x01>;
						label = "ina226-adc-avcc";
						reg = <0x4c>;
						shunt-resistor = <0x1388>;
						phandle = <0xc4>;
					};

					ina226@4d {
						compatible = "ti,ina226";
						#io-channel-cells = <0x01>;
						label = "ina226-adc-avccaux";
						reg = <0x4d>;
						shunt-resistor = <0x1388>;
						phandle = <0xc5>;
					};

					ina226@4e {
						compatible = "ti,ina226";
						#io-channel-cells = <0x01>;
						label = "ina226-dac-avcc";
						reg = <0x4e>;
						shunt-resistor = <0x1388>;
						phandle = <0xc6>;
					};
				};

				i2c@1 {
					#address-cells = <0x01>;
					#size-cells = <0x00>;
					reg = <0x01>;
				};

				i2c@2 {
					#address-cells = <0x01>;
					#size-cells = <0x00>;
					reg = <0x02>;

					irps5401@44 {
						compatible = "infineon,irps5401";
						reg = <0x44>;
						phandle = <0xf3>;
					};

					irps5401@45 {
						compatible = "infineon,irps5401";
						reg = <0x45>;
						phandle = <0xf4>;
					};
				};

				i2c@3 {
					#address-cells = <0x01>;
					#size-cells = <0x00>;
					reg = <0x03>;
				};
			};
		};

		i2c@ff030000 {
			compatible = "cdns,i2c-r1p14";
			status = "okay";
			interrupt-parent = <0x23>;
			interrupts = <0x00 0x12 0x04>;
			clock-frequency = <0x61a80>;
			reg = <0x00 0xff030000 0x00 0x1000>;
			#address-cells = <0x01>;
			#size-cells = <0x00>;
			power-domains = <0x8e 0x26>;
			clocks = <0x85 0x3e>;
			xlnx,i2c-reset = <0x00>;
			xlnx,has-interrupt = <0x2faf080>;
			xlnx,clock-freq = <0x5f5dd19>;
			xlnx,i2c-clk-freq-hz = <0x5f5dd19>;
			xlnx,ip-name = "psu_i2c";
			xlnx,iic-board-interface = "custom";
			pinctrl-names = "default\0gpio";
			pinctrl-0 = <0xad>;
			pinctrl-1 = <0xae>;
			scl-gpios = <0x59 0x10 0x06>;
			sda-gpios = <0x59 0x11 0x06>;
			phandle = <0x5b>;

			i2c-mux@74 {
				compatible = "nxp,pca9548";
				#address-cells = <0x01>;
				#size-cells = <0x00>;
				reg = <0x74>;
				i2c-mux-idle-disconnect;

				i2c@0 {
					#address-cells = <0x01>;
					#size-cells = <0x00>;
					reg = <0x00>;
					phandle = <0xf5>;

					eeprom@54 {
						compatible = "atmel,24c128";
						reg = <0x54>;
						phandle = <0xf6>;
					};
				};

				i2c@1 {
					#address-cells = <0x01>;
					#size-cells = <0x00>;
					reg = <0x01>;
					phandle = <0xf7>;

					clock-generator@36 {
						compatible = "silabs,si5341";
						reg = <0x36>;
						#clock-cells = <0x02>;
						#address-cells = <0x01>;
						#size-cells = <0x00>;
						clocks = <0xaf>;
						clock-names = "xtal";
						clock-output-names = "si5341";
						phandle = <0xb2>;

						out@2 {
							reg = <0x02>;
							always-on;
							phandle = <0xf8>;
						};

						out@3 {
							reg = <0x03>;
							always-on;
							phandle = <0xf9>;
						};

						out@5 {
							reg = <0x05>;
							always-on;
							phandle = <0xfa>;
						};

						out@6 {
							reg = <0x06>;
							always-on;
							phandle = <0xfb>;
						};

						out@9 {
							reg = <0x09>;
							always-on;
							phandle = <0xfc>;
						};
					};
				};

				i2c@2 {
					#address-cells = <0x01>;
					#size-cells = <0x00>;
					reg = <0x02>;
					phandle = <0xfd>;

					clock-generator@5d {
						#clock-cells = <0x00>;
						compatible = "silabs,si570";
						reg = <0x5d>;
						temperature-stability = <0x32>;
						factory-fout = <0x11e1a300>;
						clock-frequency = <0x11e1a300>;
						clock-output-names = "si570_user_c0";
						phandle = <0xfe>;
					};
				};

				i2c@3 {
					#address-cells = <0x01>;
					#size-cells = <0x00>;
					reg = <0x03>;
					phandle = <0xff>;

					clock-generator@5d {
						#clock-cells = <0x00>;
						compatible = "silabs,si570";
						reg = <0x5d>;
						temperature-stability = <0x32>;
						factory-fout = <0x9502f90>;
						clock-frequency = <0x9502f90>;
						clock-output-names = "si570_mgt";
						phandle = <0x100>;
					};
				};

				i2c@4 {
					#address-cells = <0x01>;
					#size-cells = <0x00>;
					reg = <0x04>;
					phandle = <0x101>;

					phc@5b {
						compatible = "idt,8a34001";
						reg = <0x5b>;
						phandle = <0x102>;
					};
				};

				i2c@5 {
					#address-cells = <0x01>;
					#size-cells = <0x00>;
					reg = <0x05>;
					phandle = <0x103>;
				};

				i2c@6 {
					#address-cells = <0x01>;
					#size-cells = <0x00>;
					reg = <0x06>;
				};
			};

			i2c-mux@75 {
				compatible = "nxp,pca9548";
				#address-cells = <0x01>;
				#size-cells = <0x00>;
				reg = <0x75>;
				i2c-mux-idle-disconnect;

				i2c@0 {
					#address-cells = <0x01>;
					#size-cells = <0x00>;
					reg = <0x00>;
				};

				i2c@1 {
					#address-cells = <0x01>;
					#size-cells = <0x00>;
					reg = <0x01>;
					phandle = <0x104>;

					clock-generator@5d {
						#clock-cells = <0x00>;
						compatible = "silabs,si570";
						reg = <0x5d>;
						temperature-stability = <0x32>;
						factory-fout = <0x11e1a300>;
						clock-frequency = <0x11e1a300>;
						clock-output-names = "si570_user_c1";
						phandle = <0x105>;
					};
				};

				i2c@2 {
					#address-cells = <0x01>;
					#size-cells = <0x00>;
					reg = <0x02>;
				};

				i2c@3 {
					#address-cells = <0x01>;
					#size-cells = <0x00>;
					reg = <0x03>;
				};

				i2c@4 {
					#address-cells = <0x01>;
					#size-cells = <0x00>;
					reg = <0x04>;
				};

				i2c@5 {
					#address-cells = <0x01>;
					#size-cells = <0x00>;
					reg = <0x05>;
				};

				i2c@6 {
					#address-cells = <0x01>;
					#size-cells = <0x00>;
					reg = <0x06>;
				};

				i2c@7 {
					#address-cells = <0x01>;
					#size-cells = <0x00>;
					reg = <0x07>;
				};
			};
		};

		memory-controller@ff960000 {
			compatible = "xlnx,zynqmp-ocmc-1.0";
			reg = <0x00 0xff960000 0x00 0x1000>;
			interrupt-parent = <0x23>;
			interrupts = <0x00 0x0a 0x04>;
			status = "okay";
			xlnx,ip-name = "psu_ocm";
			phandle = <0x66>;
		};

		perf-monitor@ffa00000 {
			compatible = "xlnx,axi-perf-monitor";
			reg = <0x00 0xffa00000 0x00 0x10000>;
			interrupts = <0x00 0x19 0x04>;
			interrupt-parent = <0x23>;
			xlnx,enable-profile = <0x00>;
			xlnx,enable-trace = <0x00>;
			xlnx,num-monitor-slots = <0x01>;
			xlnx,enable-event-count = <0x01>;
			xlnx,enable-event-log = <0x00>;
			xlnx,have-sampled-metric-cnt = <0x01>;
			xlnx,num-of-counters = <0x03>;
			xlnx,metric-count-width = <0x20>;
			xlnx,metrics-sample-count-width = <0x20>;
			xlnx,global-count-width = <0x20>;
			xlnx,metric-count-scale = <0x01>;
			clocks = <0x85 0x1f>;
			xlnx,enable-32bit-filter-id = <0x01>;
			xlnx,ip-name = "psu_apm";
			xlnx,fifo-axis-tid-width = <0x01>;
			xlnx,enable-advanced = <0x01>;
			xlnx,can-clk-freq-hz = <0x2faf080>;
			status = "okay";
			xlnx,fifo-axis-tdata-width = <0x38>;
			xlnx,fifo-axis-depth = <0x20>;
			phandle = <0x35>;
		};

		perf-monitor@fd0b0000 {
			compatible = "xlnx,axi-perf-monitor";
			reg = <0x00 0xfd0b0000 0x00 0x10000>;
			interrupts = <0x00 0x7b 0x04>;
			interrupt-parent = <0x23>;
			xlnx,enable-profile = <0x00>;
			xlnx,enable-trace = <0x00>;
			xlnx,num-monitor-slots = <0x06>;
			xlnx,enable-event-count = <0x01>;
			xlnx,enable-event-log = <0x00>;
			xlnx,have-sampled-metric-cnt = <0x01>;
			xlnx,num-of-counters = <0x0a>;
			xlnx,metric-count-width = <0x20>;
			xlnx,metrics-sample-count-width = <0x20>;
			xlnx,global-count-width = <0x20>;
			xlnx,metric-count-scale = <0x01>;
			clocks = <0x85 0x1c>;
			xlnx,enable-32bit-filter-id = <0x01>;
			xlnx,ip-name = "psu_apm";
			xlnx,fifo-axis-tid-width = <0x01>;
			xlnx,enable-advanced = <0x01>;
			xlnx,can-clk-freq-hz = <0x2faf080>;
			status = "okay";
			xlnx,fifo-axis-tdata-width = <0x38>;
			xlnx,fifo-axis-depth = <0x20>;
			phandle = <0x34>;
		};

		perf-monitor@fd490000 {
			compatible = "xlnx,axi-perf-monitor";
			reg = <0x00 0xfd490000 0x00 0x10000>;
			interrupts = <0x00 0x7b 0x04>;
			interrupt-parent = <0x23>;
			xlnx,enable-profile = <0x00>;
			xlnx,enable-trace = <0x00>;
			xlnx,num-monitor-slots = <0x01>;
			xlnx,enable-event-count = <0x01>;
			xlnx,enable-event-log = <0x00>;
			xlnx,have-sampled-metric-cnt = <0x01>;
			xlnx,num-of-counters = <0x03>;
			xlnx,metric-count-width = <0x20>;
			xlnx,metrics-sample-count-width = <0x20>;
			xlnx,global-count-width = <0x20>;
			xlnx,metric-count-scale = <0x01>;
			clocks = <0x85 0x1c>;
			xlnx,enable-32bit-filter-id = <0x01>;
			xlnx,ip-name = "psu_apm";
			xlnx,fifo-axis-tid-width = <0x01>;
			xlnx,enable-advanced = <0x01>;
			xlnx,can-clk-freq-hz = <0x2faf080>;
			status = "okay";
			xlnx,fifo-axis-tdata-width = <0x38>;
			xlnx,fifo-axis-depth = <0x20>;
			phandle = <0x37>;
		};

		perf-monitor@ffa10000 {
			compatible = "xlnx,axi-perf-monitor";
			reg = <0x00 0xffa10000 0x00 0x10000>;
			interrupts = <0x00 0x19 0x04>;
			interrupt-parent = <0x23>;
			xlnx,enable-profile = <0x00>;
			xlnx,enable-trace = <0x00>;
			xlnx,num-monitor-slots = <0x01>;
			xlnx,enable-event-count = <0x01>;
			xlnx,enable-event-log = <0x00>;
			xlnx,have-sampled-metric-cnt = <0x01>;
			xlnx,num-of-counters = <0x03>;
			xlnx,metric-count-width = <0x20>;
			xlnx,metrics-sample-count-width = <0x20>;
			xlnx,global-count-width = <0x20>;
			xlnx,metric-count-scale = <0x01>;
			clocks = <0x85 0x1f>;
			xlnx,enable-32bit-filter-id = <0x01>;
			xlnx,ip-name = "psu_apm";
			xlnx,fifo-axis-tid-width = <0x01>;
			xlnx,enable-advanced = <0x01>;
			xlnx,can-clk-freq-hz = <0x2faf080>;
			status = "okay";
			xlnx,fifo-axis-tdata-width = <0x38>;
			xlnx,fifo-axis-depth = <0x20>;
			phandle = <0x36>;
		};

		pcie@fd0e0000 {
			compatible = "xlnx,nwl-pcie-2.11";
			status = "disabled";
			#address-cells = <0x03>;
			#size-cells = <0x02>;
			#interrupt-cells = <0x01>;
			msi-controller;
			device_type = "pci";
			interrupt-parent = <0x23>;
			interrupts = <0x00 0x76 0x04 0x00 0x75 0x04 0x00 0x74 0x04 0x00 0x73 0x04 0x00 0x72 0x04>;
			interrupt-names = "misc\0dummy\0intx\0msi1\0msi0";
			msi-parent = <0xb0>;
			reg = <0x00 0xfd0e0000 0x00 0x1000 0x00 0xfd480000 0x00 0x1000 0x80 0x00 0x00 0x10000000>;
			reg-names = "breg\0pcireg\0cfg";
			ranges = <0x2000000 0x00 0xe0000000 0x00 0xe0000000 0x00 0x10000000 0x43000000 0x06 0x00 0x06 0x00 0x02 0x00>;
			bus-range = <0x00 0xff>;
			interrupt-map-mask = <0x00 0x00 0x00 0x07>;
			interrupt-map = <0x01 0xb1 0x01 0x02 0xb1 0x02 0x03 0xb1 0x03 0x04 0xb1 0x04>;
			power-domains = <0x8e 0x3b>;
			clocks = <0x85 0x17>;
			phandle = <0xb0>;

			legacy-interrupt-controller {
				interrupt-controller;
				#address-cells = <0x00>;
				#interrupt-cells = <0x01>;
				phandle = <0xb1>;
			};
		};

		spi@ff0f0000 {
			bootph-all;
			compatible = "xlnx,zynqmp-qspi-1.0";
			status = "okay";
			clock-names = "ref_clk\0pclk";
			interrupts = <0x00 0x0f 0x04>;
			interrupt-parent = <0x23>;
			num-cs = <0x02>;
			reg = <0x00 0xff0f0000 0x00 0x1000 0x00 0xc0000000 0x00 0x8000000>;
			#address-cells = <0x01>;
			#size-cells = <0x00>;
			power-domains = <0x8e 0x2d>;
			clocks = <0x85 0x35 0x85 0x1f>;
			xlnx,is-cache-coherent = <0x00>;
			xlnx,qspi-fbclk = <0x00>;
			xlnx,tz-nonsecure = <0x01>;
			xlnx,qspi-clk-freq-hz = <0x773545d>;
			xlnx,bus-width = <0x02>;
			xlnx,ip-name = "psu_qspi";
			xlnx,qspi-board-interface = "custom";
			spi-rx-bus-width = <0x04>;
			xlnx,connection-mode = <0x02>;
			spi-tx-bus-width = <0x04>;
			xlnx,clock-freq = <0x773545d>;
			xlnx,fb-clk = <0x01>;
			xlnx,qspi-mode = <0x02>;
			xlnx,qspi-bus-width = <0x02>;
			is-dual = <0x01>;
			phandle = <0x69>;

			flash@0 {
				compatible = "m25p80\0jedec,spi-nor";
				#address-cells = <0x01>;
				#size-cells = <0x01>;
				reg = <0x00 0x01>;
				parallel-memories = <0x00 0x10000000 0x00 0x10000000>;
				spi-tx-bus-width = <0x04>;
				spi-rx-bus-width = <0x04>;
				spi-max-frequency = <0x66ff300>;
				phandle = <0x02>;

				partition@0 {
					label = "qspi-boot";
					reg = <0x00 0x4000000>;
				};

				partition@1 {
					label = "qspi-bootenv";
					reg = <0x4000000 0x40000>;
				};

				partition@2 {
					label = "qspi-kernel";
					reg = <0x4040000 0x2400000>;
				};
			};
		};

		phy@fd400000 {
			compatible = "xlnx,zynqmp-psgtr-v1.1";
			status = "okay";
			reg = <0x00 0xfd400000 0x00 0x40000 0x00 0xfd3d0000 0x00 0x1000>;
			reg-names = "serdes\0siou";
			#phy-cells = <0x04>;
			xlnx,ip-name = "psu_serdes";
			clocks = <0xb2 0x00 0x02 0xb2 0x00 0x03>;
			clock-names = "ref2\0ref3";
			phandle = <0x75>;
		};

		rtc@ffa60000 {
			compatible = "xlnx,zynqmp-rtc";
			status = "okay";
			reg = <0x00 0xffa60000 0x00 0x100>;
			interrupt-parent = <0x23>;
			interrupts = <0x00 0x1a 0x04 0x00 0x1b 0x04>;
			interrupt-names = "alarm\0sec";
			calibration = <0x7fff>;
			xlnx,ip-name = "psu_rtc";
			phandle = <0x72>;
		};

		ahci@fd0c0000 {
			compatible = "ceva,ahci-1v84";
			status = "okay";
			reg = <0x00 0xfd0c0000 0x00 0x2000>;
			interrupt-parent = <0x23>;
			interrupts = <0x00 0x85 0x04>;
			power-domains = <0x8e 0x1c>;
			resets = <0x03 0x10>;
			clocks = <0x85 0x16>;
			xlnx,is-cache-coherent = <0x00>;
			xlnx,tz-nonsecure-sata0 = <0x00>;
			xlnx,ip-name = "psu_sata";
			xlnx,sata-board-interface = "custom";
			xlnx,tz-nonsecure-sata1 = <0x00>;
			ceva,p0-cominit-params = <0x18401828>;
			ceva,p0-comwake-params = <0x614080e>;
			ceva,p0-burst-params = <0x13084a06>;
			ceva,p0-retry-params = <0x96a43ffc>;
			ceva,p1-cominit-params = <0x18401828>;
			ceva,p1-comwake-params = <0x614080e>;
			ceva,p1-burst-params = <0x13084a06>;
			ceva,p1-retry-params = <0x96a43ffc>;
			phy-names = "sata-phy";
			phys = <0x75 0x03 0x01 0x01 0x03>;
			phandle = <0x73>;
		};

		mmc@ff160000 {
			bootph-all;
			compatible = "xlnx,zynqmp-8.9a\0arasan,sdhci-8.9a";
			status = "disabled";
			interrupt-parent = <0x23>;
			interrupts = <0x00 0x30 0x04>;
			reg = <0x00 0xff160000 0x00 0x1000>;
			clock-names = "clk_xin\0clk_ahb";
			#clock-cells = <0x01>;
			clock-output-names = "clk_out_sd0\0clk_in_sd0";
			power-domains = <0x8e 0x27>;
			resets = <0x03 0x26>;
			clocks = <0x85 0x36 0x85 0x1f>;
			assigned-clocks = <0x85 0x36>;
			phandle = <0x106>;
		};

		mmc@ff170000 {
			bootph-all;
			compatible = "xlnx,zynqmp-8.9a\0arasan,sdhci-8.9a";
			status = "okay";
			interrupt-parent = <0x23>;
			interrupts = <0x00 0x31 0x04>;
			reg = <0x00 0xff170000 0x00 0x1000>;
			clock-names = "clk_xin\0clk_ahb";
			#clock-cells = <0x01>;
			clock-output-names = "clk_out_sd1\0clk_in_sd1";
			power-domains = <0x8e 0x28>;
			resets = <0x03 0x27>;
			clocks = <0x85 0x37 0x85 0x1f>;
			assigned-clocks = <0x85 0x37>;
			xlnx,sd-board-interface = "custom";
			xlnx,is-cache-coherent = <0x00>;
			xlnx,clk-50-ddr-otap-dly = <0x04>;
			xlnx,clk-50-sdr-itap-dly = <0x15>;
			xlnx,has-emio = <0x00>;
			clock-frequency = <0xb2cfe8b>;
			xlnx,tz-nonsecure = <0x01>;
			xlnx,clk-100-sdr-otap-dly = <0x03>;
			xlnx,mio-bank = <0x01>;
			xlnx,ip-name = "psu_sd";
			xlnx,bus-width = <0x08>;
			xlnx,card-detect = <0x01>;
			xlnx,has-wp = <0x00>;
			xlnx,has-cd = <0x01>;
			xlnx,slot-type = <0x03>;
			xlnx,clk-50-sdr-otap-dly = <0x05>;
			xlnx,clk-50-ddr-itap-dly = <0x3d>;
			xlnx,has-power = <0x00>;
			xlnx,clk-200-sdr-otap-dly = <0x03>;
			xlnx,sdio-clk-freq-hz = <0xb2cfe8b>;
			xlnx,write-protect = <0x00>;
			disable-wp;
			no-1-8-v;
			phandle = <0x74>;
		};

		iommu@fd800000 {
			compatible = "arm,mmu-500";
			reg = <0x00 0xfd800000 0x00 0x20000>;
			#iommu-cells = <0x01>;
			status = "okay";
			#global-interrupts = <0x01>;
			interrupt-parent = <0x23>;
			interrupts = <0x00 0x9b 0x04 0x00 0x9b 0x04 0x00 0x9b 0x04 0x00 0x9b 0x04 0x00 0x9b 0x04 0x00 0x9b 0x04 0x00 0x9b 0x04 0x00 0x9b 0x04 0x00 0x9b 0x04 0x00 0x9b 0x04 0x00 0x9b 0x04 0x00 0x9b 0x04 0x00 0x9b 0x04 0x00 0x9b 0x04 0x00 0x9b 0x04 0x00 0x9b 0x04 0x00 0x9b 0x04>;
			xlnx,ip-name = "psu_smmu_gpv";
			phandle = <0x77>;
		};

		spi@ff040000 {
			compatible = "cdns,spi-r1p6";
			status = "disabled";
			interrupt-parent = <0x23>;
			interrupts = <0x00 0x13 0x04>;
			reg = <0x00 0xff040000 0x00 0x1000>;
			clock-names = "ref_clk\0pclk";
			#address-cells = <0x01>;
			#size-cells = <0x00>;
			power-domains = <0x8e 0x23>;
			clocks = <0x85 0x3a 0x85 0x1f>;
			phandle = <0x107>;
		};

		spi@ff050000 {
			compatible = "cdns,spi-r1p6";
			status = "disabled";
			interrupt-parent = <0x23>;
			interrupts = <0x00 0x14 0x04>;
			reg = <0x00 0xff050000 0x00 0x1000>;
			clock-names = "ref_clk\0pclk";
			#address-cells = <0x01>;
			#size-cells = <0x00>;
			power-domains = <0x8e 0x24>;
			clocks = <0x85 0x3b 0x85 0x1f>;
			phandle = <0x108>;
		};

		serial@ff000000 {
			bootph-all;
			compatible = "xlnx,zynqmp-uart\0cdns,uart-r1p12";
			status = "okay";
			interrupt-parent = <0x23>;
			interrupts = <0x00 0x15 0x04>;
			reg = <0x00 0xff000000 0x00 0x1000>;
			clock-names = "uart_clk\0pclk";
			power-domains = <0x8e 0x21>;
			resets = <0x03 0x22>;
			clocks = <0x85 0x38 0x85 0x1f>;
			assigned-clocks = <0x85 0x38>;
			xlnx,clock-freq = <0x5f5dd19>;
			u-boot,dm-pre-reloc;
			xlnx,uart-board-interface = "custom";
			xlnx,has-modem = <0x00>;
			xlnx,ip-name = "psu_uart";
			xlnx,baudrate = <0x1c200>;
			cts-override;
			port-number = <0x00>;
			xlnx,uart-clk-freq-hz = <0x5f5dd19>;
			phandle = <0x7d>;
		};

		serial@ff010000 {
			bootph-all;
			compatible = "xlnx,zynqmp-uart\0cdns,uart-r1p12";
			status = "disabled";
			interrupt-parent = <0x23>;
			interrupts = <0x00 0x16 0x04>;
			reg = <0x00 0xff010000 0x00 0x1000>;
			clock-names = "uart_clk\0pclk";
			power-domains = <0x8e 0x22>;
			resets = <0x03 0x23>;
			clocks = <0x85 0x39 0x85 0x1f>;
			assigned-clocks = <0x85 0x39>;
			phandle = <0x109>;
		};

		usb@ff9d0000 {
			#address-cells = <0x02>;
			#size-cells = <0x02>;
			status = "okay";
			compatible = "xlnx,zynqmp-dwc3";
			reg = <0x00 0xff9d0000 0x00 0x100>;
			clock-names = "bus_clk\0ref_clk";
			power-domains = <0x8e 0x16>;
			resets = <0x03 0x3b 0x03 0x3d 0x03 0x3f>;
			reset-names = "usb_crst\0usb_hibrst\0usb_apbrst";
			reset-gpios = <0xb3 0x01 0x01>;
			ranges;
			clocks = <0x85 0x20 0x85 0x22>;
			assigned-clocks = <0x85 0x20 0x85 0x22>;
			xlnx,is-cache-coherent = <0x00>;
			xlnx,usb-polarity = <0x00>;
			xlnx,ip-name = "psu_usb";
			xlnx,usb-reset-mode = <0x00>;
			xlnx,usb-board-interface = "custom";
			xlnx,tz-nonsecure = <0x01>;
			phy-names = "usb3-phy";
			phys = <0x75 0x02 0x04 0x00 0x02>;
			phandle = <0x7e>;

			usb@fe200000 {
				compatible = "snps,dwc3";
				status = "okay";
				reg = <0x00 0xfe200000 0x00 0x40000>;
				interrupt-parent = <0x23>;
				interrupt-names = "host\0peripheral\0otg\0wakeup";
				interrupts = <0x00 0x41 0x04 0x00 0x41 0x04 0x00 0x45 0x04 0x00 0x4b 0x04>;
				clock-names = "ref";
				snps,quirk-frame-length-adjustment = <0x20>;
				snps,resume-hs-terminations;
				clocks = <0x85 0x22>;
				xlnx,is-cache-coherent = <0x00>;
				xlnx,ip-name = "psu_usb_xhci";
				xlnx,enable-superspeed = <0x01>;
				xlnx,usb-board-interface = "custom";
				dr_mode = "host";
				snps,usb3_lpm_capable;
				maximum-speed = "super-speed";
				phandle = <0x7f>;
			};
		};

		usb@ff9e0000 {
			#address-cells = <0x02>;
			#size-cells = <0x02>;
			status = "disabled";
			compatible = "xlnx,zynqmp-dwc3";
			reg = <0x00 0xff9e0000 0x00 0x100>;
			clock-names = "bus_clk\0ref_clk";
			power-domains = <0x8e 0x17>;
			resets = <0x03 0x3c 0x03 0x3e 0x03 0x40>;
			reset-names = "usb_crst\0usb_hibrst\0usb_apbrst";
			ranges;
			clocks = <0x85 0x21 0x85 0x22>;
			assigned-clocks = <0x85 0x21 0x85 0x22>;
			phandle = <0x10a>;

			usb@fe300000 {
				compatible = "snps,dwc3";
				status = "disabled";
				reg = <0x00 0xfe300000 0x00 0x40000>;
				interrupt-parent = <0x23>;
				interrupt-names = "host\0peripheral\0otg\0wakeup";
				interrupts = <0x00 0x46 0x04 0x00 0x46 0x04 0x00 0x4a 0x04 0x00 0x4c 0x04>;
				clock-names = "ref";
				snps,quirk-frame-length-adjustment = <0x20>;
				snps,resume-hs-terminations;
				clocks = <0x85 0x22>;
				phandle = <0x10b>;
			};
		};

		watchdog@fd4d0000 {
			compatible = "cdns,wdt-r1p2";
			status = "okay";
			interrupt-parent = <0x23>;
			interrupts = <0x00 0x71 0x01>;
			reg = <0x00 0xfd4d0000 0x00 0x1000>;
			timeout-sec = <0x3c>;
			reset-on-timeout;
			clocks = <0x85 0x4b>;
			xlnx,ip-name = "psu_wdt";
			xlnx,wdt-clk-freq-hz = <0x5f5dd19>;
			xlnx,swdt-board-interface = "custom";
			phandle = <0x81>;
		};

		watchdog@ff150000 {
			compatible = "cdns,wdt-r1p2";
			status = "okay";
			interrupt-parent = <0x23>;
			interrupts = <0x00 0x34 0x01>;
			reg = <0x00 0xff150000 0x00 0x1000>;
			timeout-sec = <0x0a>;
			clocks = <0x85 0x70>;
			xlnx,ip-name = "psu_wdt";
			xlnx,wdt-clk-freq-hz = <0x5f5dd19>;
			xlnx,swdt-board-interface = "custom";
			phandle = <0x80>;
		};

		ams@ffa50000 {
			compatible = "xlnx,zynqmp-ams";
			interrupt-parent = <0x23>;
			interrupts = <0x00 0x38 0x04>;
			reg = <0x00 0xffa50000 0x00 0x800>;
			#address-cells = <0x01>;
			#size-cells = <0x01>;
			#io-channel-cells = <0x01>;
			ranges = <0x00 0x00 0xffa50800 0x800>;
			clocks = <0x85 0x46>;
			status = "okay";
			xlnx,clock-freq = <0x31>;
			xlnx,ip-name = "psu_ams";
			phandle = <0x33>;

			ams-ps@0 {
				compatible = "xlnx,zynqmp-ams-ps";
				status = "okay";
				reg = <0x00 0x400>;
				phandle = <0x05>;
			};

			ams-pl@400 {
				compatible = "xlnx,zynqmp-ams-pl";
				status = "okay";
				reg = <0x400 0x400>;
				phandle = <0x06>;
			};
		};

		dma-controller@fd4c0000 {
			compatible = "xlnx,zynqmp-dpdma";
			status = "disabled";
			reg = <0x00 0xfd4c0000 0x00 0x1000>;
			interrupts = <0x00 0x7a 0x04>;
			interrupt-parent = <0x23>;
			clock-names = "axi_clk";
			power-domains = <0x8e 0x29>;
			dma-channels = <0x06>;
			#dma-cells = <0x01>;
			clocks = <0x85 0x14>;
			assigned-clocks = <0x85 0x14>;
			phandle = <0xb4>;
		};

		display@fd4a0000 {
			bootph-all;
			compatible = "xlnx,zynqmp-dpsub-1.7";
			status = "disabled";
			reg = <0x00 0xfd4a0000 0x00 0x1000 0x00 0xfd4aa000 0x00 0x1000 0x00 0xfd4ab000 0x00 0x1000 0x00 0xfd4ac000 0x00 0x1000>;
			reg-names = "dp\0blend\0av_buf\0aud";
			interrupts = <0x00 0x77 0x04>;
			interrupt-parent = <0x23>;
			clock-names = "dp_apb_clk\0dp_aud_clk\0dp_vtc_pixel_clk_in";
			power-domains = <0x8e 0x29>;
			resets = <0x03 0x03>;
			dma-names = "vid0\0vid1\0vid2\0gfx0\0aud0\0aud1";
			dmas = <0xb4 0x00 0xb4 0x01 0xb4 0x02 0xb4 0x03 0xb4 0x04 0xb4 0x05>;
			clocks = <0x85 0x1c 0x85 0x11 0x85 0x10>;
			assigned-clocks = <0x85 0x12 0x85 0x11 0x85 0x10>;
			phandle = <0x10c>;

			ports {
				#address-cells = <0x01>;
				#size-cells = <0x00>;

				port@0 {
					reg = <0x00>;
					phandle = <0x10d>;
				};

				port@1 {
					reg = <0x01>;
					phandle = <0x10e>;
				};

				port@2 {
					reg = <0x02>;
					phandle = <0x10f>;
				};

				port@3 {
					reg = <0x03>;
					phandle = <0x110>;
				};

				port@4 {
					reg = <0x04>;
					phandle = <0x111>;
				};

				port@5 {
					reg = <0x05>;
					phandle = <0x112>;
				};
			};
		};

		coresight@fe800000 {
			compatible = "xlnx,coresight-1.0";
			status = "okay";
			reg = <0x00 0xfe800000 0x00 0x10000>;
			xlnx,ip-name = "psu_coresight_0";
			phandle = <0x3b>;
		};

		dma@ffc80000 {
			status = "okay";
			compatible = "xlnx,zynqmp-csudma-1.0";
			interrupt-parent = <0x23>;
			interrupts = <0x00 0x56 0x04>;
			reg = <0x00 0xffc80000 0x00 0x40000>;
			xlnx,ip-name = "psu_csudma";
			xlnx,dma-type = <0x00>;
			phandle = <0x3f>;
		};

		ipi@ff360000 {
			status = "disabled";
			compatible = "xlnx,zynqmp-ipi-mailbox";
			interrupt-parent = <0x23>;
			interrupts = <0x00 0x1f 0x04>;
			reg = <0x00 0xff360000 0x00 0x20>;
			xlnx,ipi-bitmask = <0x4000000>;
			xlnx,ipi-id = <0x09>;
			xlnx,ipi-buf-index = <0x05>;
			#address-cells = <0x02>;
			#size-cells = <0x02>;
			bootph-all;
			ranges;
			phandle = <0x164>;
		};

		ipi@ff370000 {
			status = "disabled";
			compatible = "xlnx,zynqmp-ipi-mailbox";
			interrupt-parent = <0x23>;
			interrupts = <0x00 0x20 0x04>;
			reg = <0x00 0xff370000 0x00 0x20>;
			xlnx,ipi-bitmask = <0x8000000>;
			xlnx,ipi-id = <0x0a>;
			xlnx,ipi-buf-index = <0x05>;
			#address-cells = <0x02>;
			#size-cells = <0x02>;
			bootph-all;
			ranges;
			phandle = <0x165>;
		};

		psu_csu@ffca0000 {
			xlnx,csu-board-interface = "custom";
			compatible = "xlnx,psu-csu-1.0";
			status = "okay";
			xlnx,can-clk-freq-hz = <0xaba9500>;
			xlnx,ip-name = "psu_csu";
			reg = <0x00 0xffca0000 0x00 0x10000>;
			phandle = <0x3e>;
		};

		psu_smmu_reg@fd5f0000 {
			compatible = "xlnx,psu-smmu-reg-1.0";
			status = "okay";
			xlnx,ip-name = "psu_smmu_reg";
			reg = <0x00 0xfd5f0000 0x00 0x10000>;
			phandle = <0x78>;
		};

		psu_cci_reg@fd5e0000 {
			compatible = "xlnx,psu-cci-reg-1.0";
			status = "okay";
			xlnx,ip-name = "psu_cci_reg";
			reg = <0x00 0xfd5e0000 0x00 0x10000>;
			phandle = <0x3a>;
		};

		psu_afi@fd3b0000 {
			compatible = "xlnx,psu-afi-1.0";
			status = "okay";
			xlnx,ip-name = "psu_afi";
			reg = <0x00 0xfd3b0000 0x00 0x10000>;
			phandle = <0x31>;
		};

		psu_afi@fd3a0000 {
			compatible = "xlnx,psu-afi-1.0";
			status = "okay";
			xlnx,ip-name = "psu_afi";
			reg = <0x00 0xfd3a0000 0x00 0x10000>;
			phandle = <0x30>;
		};

		psu_afi@fd390000 {
			compatible = "xlnx,psu-afi-1.0";
			status = "okay";
			xlnx,ip-name = "psu_afi";
			reg = <0x00 0xfd390000 0x00 0x10000>;
			phandle = <0x2f>;
		};

		psu_afi@fd380000 {
			compatible = "xlnx,psu-afi-1.0";
			status = "okay";
			xlnx,ip-name = "psu_afi";
			reg = <0x00 0xfd380000 0x00 0x10000>;
			phandle = <0x2e>;
		};

		psu_afi@fd370000 {
			xlnx,is-cache-coherent = <0x00>;
			compatible = "xlnx,psu-afi-1.0";
			status = "okay";
			xlnx,ip-name = "psu_afi";
			reg = <0x00 0xfd370000 0x00 0x10000>;
			phandle = <0x2d>;
		};

		psu_afi@fd360000 {
			xlnx,is-cache-coherent = <0x00>;
			compatible = "xlnx,psu-afi-1.0";
			status = "okay";
			xlnx,ip-name = "psu_afi";
			reg = <0x00 0xfd360000 0x00 0x10000>;
			phandle = <0x2c>;
		};

		psu_afi@ff9b0000 {
			compatible = "xlnx,psu-afi-1.0";
			status = "okay";
			xlnx,ip-name = "psu_afi";
			reg = <0x00 0xff9b0000 0x00 0x10000>;
			phandle = <0x32>;
		};

		PERIPHERAL@ff380000 {
			compatible = "xlnx,PERIPHERAL-1.0";
			reg = <0x00 0xff380000 0x00 0x80000>;
			phandle = <0x40>;
		};

		PERIPHERAL@ff990000 {
			compatible = "xlnx,PERIPHERAL-1.0";
			reg = <0x00 0xff990000 0x00 0x10000>;
			phandle = <0x65>;
		};

		psu_iouslcr@ff180000 {
			compatible = "xlnx,psu-iouslcr-1.0";
			status = "okay";
			xlnx,ip-name = "psu_iouslcr";
			reg = <0x00 0xff180000 0x00 0xc0000>;
			phandle = <0x5f>;
		};

		psu_qspi_linear@c0000000 {
			reg = <0x00 0xc0000000 0x00 0x20000000>;
			phandle = <0x16c>;
		};

		interrupt-controller@f9010000 {
			phandle = <0x23>;
			xlnx,ip-name = "psu_acpu_gic";
			status = "okay";
			interrupts = <0x01 0x09 0xf04>;
			interrupt-parent = <0x23>;
			interrupt-controller;
			reg = <0x00 0xf9010000 0x00 0x10000 0x00 0xf9020000 0x00 0x20000 0x00 0xf9040000 0x00 0x20000 0x00 0xf9060000 0x00 0x20000>;
			#interrupt-cells = <0x03>;
			compatible = "arm,gic-400";
		};
	};

	indirect-bus@1 {
		compatible = "indirect-bus";
		#address-cells = <0x02>;
		#size-cells = <0x02>;
		phandle = <0x16d>;

		xppu@ff980000 {
			compatible = "xlnx,xppu";
			#firewall-cells = <0x00>;
			reg = <0x00 0xff980000 0x00 0x1000>;
			status = "okay";
			xlnx,ip-name = "psu_lpd_xppu";
			phandle = <0x62>;
		};
	};

	binman {
		phandle = <0x16e>;
	};

	pss-ref-clk {
		bootph-all;
		compatible = "fixed-clock";
		#clock-cells = <0x00>;
		clock-frequency = <0x1fca055>;
		clock-output-names = "pss_ref_clk";
		phandle = <0x9f>;
	};

	video-clk {
		bootph-all;
		compatible = "fixed-clock";
		#clock-cells = <0x00>;
		clock-frequency = <0x19bfcc0>;
		clock-output-names = "video_clk";
		phandle = <0xa0>;
	};

	pss-alt-ref-clk {
		bootph-all;
		compatible = "fixed-clock";
		#clock-cells = <0x00>;
		clock-frequency = <0x00>;
		clock-output-names = "pss_alt_ref_clk";
		phandle = <0xa1>;
	};

	gt-crx-ref-clk {
		bootph-all;
		compatible = "fixed-clock";
		#clock-cells = <0x00>;
		clock-frequency = <0x66ff300>;
		clock-output-names = "gt_crx_ref_clk";
		phandle = <0xa3>;
	};

	aux-ref-clk {
		bootph-all;
		compatible = "fixed-clock";
		#clock-cells = <0x00>;
		clock-frequency = <0x19bfcc0>;
		clock-output-names = "aux_ref_clk";
		phandle = <0xa2>;
	};

	amba_pl {
		ranges;
		compatible = "simple-bus";
		#address-cells = <0x02>;
		#size-cells = <0x02>;
		firmware-name = "49_trdPllOnddr_dacddr_adcmts.bit.bin";
		phandle = <0x16f>;

		clk_wiz@b4c30000 {
			reg = <0x00 0xb4c30000 0x00 0x10000>;
			clock-names = "clk_in1\0clk_in2\0s_axi_aclk";
			xlnx,nr-outputs = <0x01>;
			compatible = "xlnx,clk-wiz-6.0\0xlnx,versal-clk-wizard";
			xlnx,speed-grade = <0x02>;
			clocks = <0xb5 0xb5 0x85 0x47>;
			#clock-cells = <0x01>;
			phandle = <0x1e>;
		};

		clk_wiz@b4c20000 {
			reg = <0x00 0xb4c20000 0x00 0x10000>;
			clock-names = "clk_in1\0clk_in2\0s_axi_aclk";
			xlnx,nr-outputs = <0x01>;
			compatible = "xlnx,clk-wiz-6.0\0xlnx,versal-clk-wizard";
			xlnx,speed-grade = <0x02>;
			clocks = <0xb5 0xb5 0x85 0x47>;
			#clock-cells = <0x01>;
			phandle = <0x1d>;
		};

		clk_wiz@b4c10000 {
			reg = <0x00 0xb4c10000 0x00 0x10000>;
			clock-names = "clk_in1\0clk_in2\0s_axi_aclk";
			xlnx,nr-outputs = <0x01>;
			compatible = "xlnx,clk-wiz-6.0\0xlnx,versal-clk-wizard";
			xlnx,speed-grade = <0x02>;
			clocks = <0xb5 0xb5 0x85 0x47>;
			#clock-cells = <0x01>;
			phandle = <0x1c>;
		};

		clk_wiz@b4c00000 {
			reg = <0x00 0xb4c00000 0x00 0x10000>;
			clock-names = "clk_in1\0clk_in2\0s_axi_aclk";
			xlnx,nr-outputs = <0x01>;
			compatible = "xlnx,clk-wiz-6.0\0xlnx,versal-clk-wizard";
			xlnx,speed-grade = <0x02>;
			clocks = <0xb5 0xb5 0x85 0x47>;
			#clock-cells = <0x01>;
			phandle = <0x1b>;
		};

		clk_wiz@b4c70000 {
			reg = <0x00 0xb4c70000 0x00 0x10000>;
			clock-names = "clk_in1\0s_axi_aclk";
			xlnx,nr-outputs = <0x01>;
			compatible = "xlnx,clk-wiz-6.0\0xlnx,versal-clk-wizard";
			xlnx,speed-grade = <0x02>;
			clocks = <0xb6 0x85 0x47>;
			#clock-cells = <0x01>;
			phandle = <0x22>;
		};

		clk_wiz@b4c60000 {
			reg = <0x00 0xb4c60000 0x00 0x10000>;
			clock-names = "clk_in1\0s_axi_aclk";
			xlnx,nr-outputs = <0x01>;
			compatible = "xlnx,clk-wiz-6.0\0xlnx,versal-clk-wizard";
			xlnx,speed-grade = <0x02>;
			clocks = <0xb6 0x85 0x47>;
			#clock-cells = <0x01>;
			phandle = <0x21>;
		};

		clk_wiz@b4c50000 {
			reg = <0x00 0xb4c50000 0x00 0x10000>;
			clock-names = "clk_in1\0s_axi_aclk";
			xlnx,nr-outputs = <0x01>;
			compatible = "xlnx,clk-wiz-6.0\0xlnx,versal-clk-wizard";
			xlnx,speed-grade = <0x02>;
			clocks = <0xb6 0x85 0x47>;
			#clock-cells = <0x01>;
			phandle = <0x20>;
		};

		clk_wiz@b4c40000 {
			reg = <0x00 0xb4c40000 0x00 0x10000>;
			clock-names = "clk_in1\0clk_in2\0clkfb_in\0s_axi_aclk";
			xlnx,nr-outputs = <0x01>;
			compatible = "xlnx,clk-wiz-6.0\0xlnx,versal-clk-wizard";
			xlnx,speed-grade = <0x02>;
			clocks = <0xb6 0xb6 0xb7 0x85 0x47>;
			#clock-cells = <0x01>;
			phandle = <0x1f>;
		};

		misc_clk_1 {
			clock-div = <0x01>;
			compatible = "fixed-factor-clock";
			clock-mult = <0x01>;
			clocks = <0x85 0x47>;
			#clock-cells = <0x00>;
			phandle = <0xb7>;
		};

		misc_clk_3 {
			clock-div = <0x01>;
			compatible = "fixed-factor-clock";
			clock-mult = <0x03>;
			clocks = <0x85 0x47>;
			#clock-cells = <0x00>;
			phandle = <0xb8>;
		};

		misc_clk_2 {
			clock-div = <0x01>;
			compatible = "fixed-factor-clock";
			clock-mult = <0x05>;
			clocks = <0x85 0x47>;
			#clock-cells = <0x00>;
			phandle = <0xb5>;
		};

		misc_clk_0 {
			clock-div = <0x01>;
			compatible = "fixed-factor-clock";
			clock-mult = <0x03>;
			clocks = <0x85 0x47>;
			#clock-cells = <0x00>;
			phandle = <0xb6>;
		};

		dma@a0203000 {
			interrupts = <0x00 0x5b 0x04>;
			compatible = "xlnx,axi-dma-7.1\0xlnx,axi-dma-1.00.a";
			xlnx,s2mm-data-width = <0x100>;
			xlnx,mm2s-burst-size = <0x10>;
			xlnx,m-axi-mm2s-data-width = <0x20>;
			xlnx,num-s2mm-channels = <0x01>;
			xlnx,dlytmr-resolution = <0x7d>;
			interrupt-parent = <0x23>;
			xlnx,sg-length-width = <0x1a>;
			xlnx,prmry-is-aclk-async = <0x01>;
			xlnx,include-s2mm-sf = <0x01>;
			#dma-cells = <0x01>;
			xlnx,ip-name = "axi_dma";
			xlnx,single-interface = <0x00>;
			xlnx,sg-include-stscntrl-strm = <0x00>;
			xlnx,include-s2mm-dre = <0x00>;
			reg = <0x00 0xa0203000 0x00 0x1000>;
			xlnx,addr-width = <0x40>;
			xlnx,include-s2mm = <0x01>;
			clocks = <0xb8 0x85 0x47 0x85 0x47>;
			xlnx,s-axis-s2mm-tdata-width = <0x100>;
			xlnx,micro-dma = <0x00>;
			xlnx,increase-throughput = <0x00>;
			xlnx,mm2s-data-width = <0x20>;
			xlnx,addrwidth = <0x40>;
			xlnx,include-sg;
			xlnx,sg-use-stsapp-length = <0x00>;
			xlnx,m-axis-mm2s-tdata-width = <0x20>;
			xlnx,edk-iptype = "PERIPHERAL";
			xlnx,s2mm-burst-size = <0x40>;
			xlnx,m-axi-s2mm-data-width = <0x100>;
			xlnx,num-mm2s-channels = <0x01>;
			xlnx,enable-multi-channel = <0x00>;
			status = "okay";
			xlnx,include-mm2s-sf = <0x01>;
			clock-names = "m_axi_s2mm_aclk\0m_axi_sg_aclk\0s_axi_lite_aclk";
			interrupt-names = "s2mm_introut";
			xlnx,include-mm2s = <0x00>;
			xlnx,include-mm2s-dre = <0x00>;
			phandle = <0x11>;

			dma-channel@a0203030 {
				interrupts = <0x00 0x5b 0x04>;
				xlnx,datawidth = <0x100>;
				xlnx,device-id = <0x00>;
				compatible = "xlnx,axi-dma-s2mm-channel";
				dma-channels = <0x01>;
				phandle = <0x172>;
			};
		};

		axis_switch@a0204000 {
			xlnx,m14-s13-connectivity = <0x01>;
			xlnx,m13-s06-connectivity = <0x01>;
			xlnx,m04-s15-connectivity = <0x01>;
			xlnx,m12-s00-connectivity = <0x01>;
			xlnx,m03-s08-connectivity = <0x01>;
			xlnx,m02-s02-connectivity = <0x01>;
			xlnx,m12-s12-connectivity = <0x01>;
			xlnx,m11-s05-connectivity = <0x01>;
			reg = <0x00 0xa0204000 0x00 0x1000>;
			xlnx,m02-s14-connectivity = <0x01>;
			xlnx,s-axi-ctrl-addr-width = <0x07>;
			xlnx,m01-s07-connectivity = <0x01>;
			xlnx,m00-s01-connectivity = <0x01>;
			xlnx,m10-s11-connectivity = <0x01>;
			xlnx,m09-s11-connectivity = <0x01>;
			xlnx,m00-s13-connectivity = <0x01>;
			xlnx,m08-s04-connectivity = <0x01>;
			xlnx,tdata-num-bytes = <0x20>;
			xlnx,m07-s09-connectivity = <0x01>;
			xlnx,m07-s10-connectivity = <0x01>;
			xlnx,m06-s03-connectivity = <0x01>;
			xlnx,m15-s06-connectivity = <0x01>;
			xlnx,m06-s15-connectivity = <0x01>;
			xlnx,m14-s00-connectivity = <0x01>;
			xlnx,m05-s08-connectivity = <0x01>;
			xlnx,m04-s02-connectivity = <0x01>;
			xlnx,m14-s12-connectivity = <0x01>;
			xlnx,m13-s05-connectivity = <0x01>;
			xlnx,m04-s14-connectivity = <0x01>;
			xlnx,m03-s07-connectivity = <0x01>;
			xlnx,m02-s01-connectivity = <0x01>;
			xlnx,log-si-slots = <0x04>;
			xlnx,m12-s11-connectivity = <0x01>;
			xlnx,m11-s04-connectivity = <0x01>;
			xlnx,m02-s13-connectivity = <0x01>;
			xlnx,m01-s06-connectivity = <0x01>;
			xlnx,num-si = <0x10>;
			xlnx,m00-s00-connectivity = <0x01>;
			xlnx,m10-s10-connectivity = <0x01>;
			xlnx,m10-s09-connectivity = <0x01>;
			xlnx,m09-s09-connectivity = <0x01>;
			xlnx,m09-s10-connectivity = <0x01>;
			xlnx,m00-s12-connectivity = <0x01>;
			xlnx,m08-s03-connectivity = <0x01>;
			xlnx,m08-s15-connectivity = <0x01>;
			xlnx,has-tstrb = <0x00>;
			xlnx,m07-s08-connectivity = <0x01>;
			xlnx,m06-s02-connectivity = <0x01>;
			xlnx,has-tready = <0x01>;
			xlnx,m15-s05-connectivity = <0x01>;
			xlnx,arb-on-num-cycles = <0x00>;
			xlnx,m06-s14-connectivity = <0x01>;
			xlnx,m05-s07-connectivity = <0x01>;
			xlnx,m04-s01-connectivity = <0x01>;
			clock-names = "aclk\0s_axi_ctrl_aclk";
			xlnx,m14-s11-connectivity = <0x01>;
			xlnx,m13-s04-connectivity = <0x01>;
			xlnx,m04-s13-connectivity = <0x01>;
			xlnx,routing-mode = <0x01>;
			xlnx,m03-s06-connectivity = <0x01>;
			xlnx,m02-s00-connectivity = <0x01>;
			xlnx,m12-s10-connectivity = <0x01>;
			xlnx,m12-s09-connectivity = <0x01>;
			xlnx,m11-s03-connectivity = <0x01>;
			xlnx,m02-s12-connectivity = <0x01>;
			xlnx,m01-s05-connectivity = <0x01>;
			xlnx,axis-tid-width = <0x01>;
			xlnx,m11-s15-connectivity = <0x01>;
			xlnx,m10-s08-connectivity = <0x01>;
			xlnx,has-tkeep = <0x01>;
			xlnx,m09-s08-connectivity = <0x01>;
			xlnx,m00-s11-connectivity = <0x01>;
			xlnx,m08-s02-connectivity = <0x01>;
			xlnx,m08-s14-connectivity = <0x01>;
			xlnx,m07-s07-connectivity = <0x01>;
			xlnx,m06-s01-connectivity = <0x01>;
			xlnx,m15-s04-connectivity = <0x01>;
			xlnx,m06-s13-connectivity = <0x01>;
			xlnx,m05-s06-connectivity = <0x01>;
			xlnx,m04-s00-connectivity = <0x01>;
			xlnx,m14-s10-connectivity = <0x01>;
			xlnx,m14-s09-connectivity = <0x01>;
			xlnx,has-aclken = <0x00>;
			xlnx,tuser-width = <0x00>;
			xlnx,m13-s03-connectivity = <0x01>;
			xlnx,m04-s12-connectivity = <0x01>;
			xlnx,arb-algorithm = <0x00>;
			xlnx,m03-s05-connectivity = <0x01>;
			xlnx,m13-s15-connectivity = <0x01>;
			xlnx,m12-s08-connectivity = <0x01>;
			xlnx,arb-on-tlast = <0x00>;
			xlnx,m11-s02-connectivity = <0x01>;
			xlnx,m02-s11-connectivity = <0x01>;
			xlnx,tid-width = <0x00>;
			xlnx,m01-s04-connectivity = <0x01>;
			xlnx,m11-s14-connectivity = <0x01>;
			xlnx,m10-s07-connectivity = <0x01>;
			xlnx,has-tlast = <0x00>;
			xlnx,m09-s07-connectivity = <0x01>;
			xlnx,m00-s10-connectivity = <0x01>;
			xlnx,m00-s09-connectivity = <0x01>;
			xlnx,common-clock = <0x00>;
			xlnx,axis-tuser-width = <0x01>;
			xlnx,m08-s01-connectivity = <0x01>;
			xlnx,m08-s13-connectivity = <0x01>;
			xlnx,m07-s06-connectivity = <0x01>;
			xlnx,m06-s00-connectivity = <0x01>;
			xlnx,m15-s03-connectivity = <0x01>;
			xlnx,m06-s12-connectivity = <0x01>;
			xlnx,m05-s05-connectivity = <0x01>;
			xlnx,m15-s15-connectivity = <0x01>;
			xlnx,m14-s08-connectivity = <0x01>;
			status = "okay";
			xlnx,m13-s02-connectivity = <0x01>;
			xlnx,m04-s11-connectivity = <0x01>;
			xlnx,m03-s04-connectivity = <0x01>;
			xlnx,tdest-width = <0x00>;
			xlnx,m13-s14-connectivity = <0x01>;
			xlnx,m12-s07-connectivity = <0x01>;
			xlnx,m11-s01-connectivity = <0x01>;
			xlnx,m02-s09-connectivity = <0x01>;
			xlnx,m02-s10-connectivity = <0x01>;
			xlnx,m01-s03-connectivity = <0x01>;
			xlnx,m11-s13-connectivity = <0x01>;
			xlnx,arb-on-max-xfers = <0x01>;
			xlnx,m10-s06-connectivity = <0x01>;
			xlnx,m01-s15-connectivity = <0x01>;
			xlnx,m09-s06-connectivity = <0x01>;
			xlnx,m00-s08-connectivity = <0x01>;
			xlnx,m08-s00-connectivity = <0x01>;
			xlnx,include-arbiter = <0x01>;
			xlnx,num-si-slots = <0x10>;
			xlnx,axis-tdest-width = <0x01>;
			xlnx,edk-iptype = "PERIPHERAL";
			xlnx,m08-s12-connectivity = <0x01>;
			xlnx,m07-s05-connectivity = <0x01>;
			xlnx,m15-s02-connectivity = <0x01>;
			xlnx,m06-s11-connectivity = <0x01>;
			xlnx,m05-s04-connectivity = <0x01>;
			xlnx,m15-s14-connectivity = <0x01>;
			xlnx,m14-s07-connectivity = <0x01>;
			xlnx,m13-s01-connectivity = <0x01>;
			xlnx,m04-s09-connectivity = <0x01>;
			xlnx,m04-s10-connectivity = <0x01>;
			xlnx,m03-s03-connectivity = <0x01>;
			xlnx,m13-s13-connectivity = <0x01>;
			xlnx,m12-s06-connectivity = <0x01>;
			xlnx,m03-s15-connectivity = <0x01>;
			xlnx,m11-s00-connectivity = <0x01>;
			xlnx,m02-s08-connectivity = <0x01>;
			xlnx,m01-s02-connectivity = <0x01>;
			xlnx,m11-s12-connectivity = <0x01>;
			xlnx,m10-s05-connectivity = <0x01>;
			xlnx,m01-s14-connectivity = <0x01>;
			xlnx,m09-s05-connectivity = <0x01>;
			xlnx,m00-s07-connectivity = <0x01>;
			xlnx,m08-s11-connectivity = <0x01>;
			xlnx,m07-s04-connectivity = <0x01>;
			xlnx,m15-s01-connectivity = <0x01>;
			xlnx,m06-s09-connectivity = <0x01>;
			xlnx,m06-s10-connectivity = <0x01>;
			xlnx,m05-s03-connectivity = <0x01>;
			xlnx,m15-s13-connectivity = <0x01>;
			xlnx,m14-s06-connectivity = <0x01>;
			xlnx,m05-s15-connectivity = <0x01>;
			xlnx,m13-s00-connectivity = <0x01>;
			xlnx,m04-s08-connectivity = <0x01>;
			xlnx,m03-s02-connectivity = <0x01>;
			xlnx,m13-s12-connectivity = <0x01>;
			xlnx,m12-s05-connectivity = <0x01>;
			xlnx,m03-s14-connectivity = <0x01>;
			compatible = "xlnx,axis-switch-1.1";
			xlnx,m02-s07-connectivity = <0x01>;
			xlnx,m01-s01-connectivity = <0x01>;
			xlnx,output-reg = <0x00>;
			xlnx,m11-s11-connectivity = <0x01>;
			xlnx,num-mi-slots = <0x01>;
			xlnx,m10-s04-connectivity = <0x01>;
			xlnx,m01-s13-connectivity = <0x01>;
			xlnx,m09-s04-connectivity = <0x01>;
			xlnx,m00-s06-connectivity = <0x01>;
			xlnx,m08-s09-connectivity = <0x01>;
			xlnx,m08-s10-connectivity = <0x01>;
			xlnx,m07-s03-connectivity = <0x01>;
			xlnx,m07-s15-connectivity = <0x01>;
			xlnx,m15-s00-connectivity = <0x01>;
			xlnx,m06-s08-connectivity = <0x01>;
			xlnx,m05-s02-connectivity = <0x01>;
			xlnx,m15-s12-connectivity = <0x01>;
			xlnx,m14-s05-connectivity = <0x01>;
			xlnx,m05-s14-connectivity = <0x01>;
			xlnx,m04-s07-connectivity = <0x01>;
			xlnx,m03-s01-connectivity = <0x01>;
			xlnx,m13-s11-connectivity = <0x01>;
			xlnx,m12-s04-connectivity = <0x01>;
			xlnx,m03-s13-connectivity = <0x01>;
			xlnx,m02-s06-connectivity = <0x01>;
			xlnx,m01-s00-connectivity = <0x01>;
			xlnx,m11-s10-connectivity = <0x01>;
			xlnx,m11-s09-connectivity = <0x01>;
			xlnx,m10-s03-connectivity = <0x01>;
			xlnx,m01-s12-connectivity = <0x01>;
			xlnx,m09-s03-connectivity = <0x01>;
			xlnx,m00-s05-connectivity = <0x01>;
			xlnx,m10-s15-connectivity = <0x01>;
			xlnx,s-axi-ctrl-data-width = <0x20>;
			xlnx,m09-s15-connectivity = <0x01>;
			xlnx,m08-s08-connectivity = <0x01>;
			xlnx,m07-s02-connectivity = <0x01>;
			xlnx,m07-s14-connectivity = <0x01>;
			xlnx,m06-s07-connectivity = <0x01>;
			xlnx,m05-s01-connectivity = <0x01>;
			xlnx,m15-s11-connectivity = <0x01>;
			xlnx,m14-s04-connectivity = <0x01>;
			xlnx,m05-s13-connectivity = <0x01>;
			xlnx,m04-s06-connectivity = <0x01>;
			xlnx,m03-s00-connectivity = <0x01>;
			xlnx,m13-s10-connectivity = <0x01>;
			xlnx,m13-s09-connectivity = <0x01>;
			xlnx,m12-s03-connectivity = <0x01>;
			xlnx,m03-s12-connectivity = <0x01>;
			xlnx,m02-s05-connectivity = <0x01>;
			xlnx,m12-s15-connectivity = <0x01>;
			xlnx,m11-s08-connectivity = <0x01>;
			xlnx,m01-s11-connectivity = <0x01>;
			xlnx,m09-s02-connectivity = <0x01>;
			xlnx,m10-s02-connectivity = <0x01>;
			xlnx,m00-s04-connectivity = <0x01>;
			xlnx,m10-s14-connectivity = <0x01>;
			xlnx,ip-name = "axis_switch";
			xlnx,m09-s14-connectivity = <0x01>;
			xlnx,m08-s07-connectivity = <0x01>;
			xlnx,m07-s01-connectivity = <0x01>;
			xlnx,m07-s13-connectivity = <0x01>;
			xlnx,m06-s06-connectivity = <0x01>;
			xlnx,m05-s00-connectivity = <0x01>;
			xlnx,m15-s10-connectivity = <0x01>;
			xlnx,m15-s09-connectivity = <0x01>;
			xlnx,m14-s03-connectivity = <0x01>;
			xlnx,m05-s12-connectivity = <0x01>;
			xlnx,m04-s05-connectivity = <0x01>;
			xlnx,m14-s15-connectivity = <0x01>;
			xlnx,m13-s08-connectivity = <0x01>;
			xlnx,m12-s02-connectivity = <0x01>;
			xlnx,m03-s11-connectivity = <0x01>;
			xlnx,m02-s04-connectivity = <0x01>;
			xlnx,m12-s14-connectivity = <0x01>;
			xlnx,m11-s07-connectivity = <0x01>;
			xlnx,m01-s09-connectivity = <0x01>;
			xlnx,m01-s10-connectivity = <0x01>;
			xlnx,m09-s01-connectivity = <0x01>;
			xlnx,m10-s01-connectivity = <0x01>;
			xlnx,m00-s03-connectivity = <0x01>;
			xlnx,m10-s13-connectivity = <0x01>;
			xlnx,m09-s13-connectivity = <0x01>;
			xlnx,m00-s15-connectivity = <0x01>;
			xlnx,m08-s06-connectivity = <0x01>;
			xlnx,m07-s00-connectivity = <0x01>;
			xlnx,m07-s12-connectivity = <0x01>;
			xlnx,m06-s05-connectivity = <0x01>;
			xlnx,m15-s08-connectivity = <0x01>;
			xlnx,m14-s02-connectivity = <0x01>;
			xlnx,m05-s11-connectivity = <0x01>;
			clocks = <0xb8 0x85 0x47>;
			xlnx,m04-s04-connectivity = <0x01>;
			xlnx,num-mi = <0x01>;
			xlnx,m14-s14-connectivity = <0x01>;
			xlnx,m13-s07-connectivity = <0x01>;
			xlnx,m12-s01-connectivity = <0x01>;
			xlnx,m03-s09-connectivity = <0x01>;
			xlnx,m03-s10-connectivity = <0x01>;
			xlnx,m02-s03-connectivity = <0x01>;
			xlnx,m12-s13-connectivity = <0x01>;
			xlnx,m11-s06-connectivity = <0x01>;
			xlnx,m02-s15-connectivity = <0x01>;
			xlnx,m01-s08-connectivity = <0x01>;
			xlnx,m09-s00-connectivity = <0x01>;
			xlnx,m10-s00-connectivity = <0x01>;
			xlnx,m00-s02-connectivity = <0x01>;
			xlnx,m10-s12-connectivity = <0x01>;
			xlnx,m09-s12-connectivity = <0x01>;
			xlnx,m00-s14-connectivity = <0x01>;
			xlnx,m08-s05-connectivity = <0x01>;
			xlnx,m07-s11-connectivity = <0x01>;
			xlnx,m06-s04-connectivity = <0x01>;
			xlnx,axis-tdata-width = <0x100>;
			xlnx,m15-s07-connectivity = <0x01>;
			xlnx,m14-s01-connectivity = <0x01>;
			xlnx,m05-s09-connectivity = <0x01>;
			xlnx,m05-s10-connectivity = <0x01>;
			xlnx,m04-s03-connectivity = <0x01>;
			xlnx,decoder-reg = <0x00>;
			phandle = <0x12>;
		};

		tlast_gen_v1_0@a0310000 {
			xlnx,s00-axi-data-width = <0x20>;
			compatible = "xlnx,tlast-gen-v1-0-1.0";
			status = "okay";
			clock-names = "aclk\0s00_axi_aclk";
			xlnx,s00-axi-addr-width = <0x04>;
			xlnx,ip-name = "tlast_gen_v1_0";
			xlnx,edk-iptype = "PERIPHERAL";
			reg = <0x00 0xa0310000 0x00 0x1000>;
			clocks = <0xb8 0x85 0x47>;
			phandle = <0x16>;
		};

		dma@a0000000 {
			interrupts = <0x00 0x5a 0x04>;
			compatible = "xlnx,axi-dma-7.1\0xlnx,axi-dma-1.00.a";
			xlnx,s2mm-data-width = <0x20>;
			xlnx,mm2s-burst-size = <0x40>;
			xlnx,m-axi-mm2s-data-width = <0x100>;
			xlnx,num-s2mm-channels = <0x01>;
			xlnx,dlytmr-resolution = <0x7d>;
			interrupt-parent = <0x23>;
			xlnx,sg-length-width = <0x1a>;
			xlnx,prmry-is-aclk-async = <0x01>;
			xlnx,include-s2mm-sf = <0x01>;
			#dma-cells = <0x01>;
			xlnx,ip-name = "axi_dma";
			xlnx,single-interface = <0x00>;
			xlnx,sg-include-stscntrl-strm = <0x00>;
			xlnx,include-s2mm-dre = <0x00>;
			reg = <0x00 0xa0000000 0x00 0x10000>;
			xlnx,addr-width = <0x40>;
			xlnx,include-s2mm = <0x00>;
			clocks = <0xb8 0x85 0x47 0x85 0x47>;
			xlnx,s-axis-s2mm-tdata-width = <0x20>;
			xlnx,micro-dma = <0x00>;
			xlnx,increase-throughput = <0x00>;
			xlnx,mm2s-data-width = <0x100>;
			xlnx,addrwidth = <0x40>;
			xlnx,include-sg;
			xlnx,sg-use-stsapp-length = <0x00>;
			xlnx,m-axis-mm2s-tdata-width = <0x100>;
			xlnx,edk-iptype = "PERIPHERAL";
			xlnx,s2mm-burst-size = <0x10>;
			xlnx,m-axi-s2mm-data-width = <0x20>;
			xlnx,num-mm2s-channels = <0x01>;
			xlnx,enable-multi-channel = <0x00>;
			status = "okay";
			xlnx,include-mm2s-sf = <0x01>;
			clock-names = "m_axi_mm2s_aclk\0m_axi_sg_aclk\0s_axi_lite_aclk";
			interrupt-names = "mm2s_introut";
			xlnx,include-mm2s = <0x01>;
			xlnx,include-mm2s-dre = <0x01>;
			phandle = <0x0f>;

			dma-channel@a0000000 {
				interrupts = <0x00 0x5a 0x04>;
				xlnx,datawidth = <0x100>;
				xlnx,device-id = <0x01>;
				compatible = "xlnx,axi-dma-mm2s-channel";
				xlnx,include-dre;
				dma-channels = <0x01>;
				phandle = <0x173>;
			};
		};

		gpio@a0240000 {
			xlnx,gpio-board-interface = "Custom";
			compatible = "xlnx,axi-gpio-2.0\0xlnx,xps-gpio-1.00.a";
			xlnx,all-outputs = <0x01>;
			#gpio-cells = <0x02>;
			xlnx,gpio-width = <0x01>;
			xlnx,dout-default = <0x0f>;
			xlnx,is-dual = <0x00>;
			xlnx,ip-name = "axi_gpio";
			xlnx,tri-default-2 = <0xffffffff>;
			reg = <0x00 0xa0240000 0x00 0x1000>;
			xlnx,all-inputs-2 = <0x00>;
			clocks = <0x85 0x47>;
			xlnx,all-outputs-2 = <0x00>;
			gpio-controller;
			xlnx,interrupt-present = <0x00>;
			xlnx,gpio2-board-interface = "Custom";
			xlnx,edk-iptype = "PERIPHERAL";
			xlnx,dout-default-2 = <0x00>;
			status = "okay";
			xlnx,gpio2-width = <0x20>;
			clock-names = "s_axi_aclk";
			xlnx,tri-default = <0xffffffff>;
			xlnx,all-inputs = <0x00>;
			phandle = <0x14>;
		};

		gpio@a0202000 {
			xlnx,gpio-board-interface = "Custom";
			compatible = "xlnx,axi-gpio-2.0\0xlnx,xps-gpio-1.00.a";
			xlnx,all-outputs = <0x01>;
			#gpio-cells = <0x02>;
			xlnx,gpio-width = <0x10>;
			xlnx,dout-default = <0x00>;
			xlnx,is-dual = <0x00>;
			xlnx,ip-name = "axi_gpio";
			xlnx,tri-default-2 = <0xffffffff>;
			reg = <0x00 0xa0202000 0x00 0x1000>;
			xlnx,all-inputs-2 = <0x00>;
			clocks = <0x85 0x47>;
			xlnx,all-outputs-2 = <0x00>;
			gpio-controller;
			xlnx,interrupt-present = <0x00>;
			xlnx,gpio2-board-interface = "Custom";
			xlnx,edk-iptype = "PERIPHERAL";
			xlnx,dout-default-2 = <0x00>;
			status = "okay";
			xlnx,gpio2-width = <0x20>;
			clock-names = "s_axi_aclk";
			xlnx,tri-default = <0xffffffff>;
			xlnx,all-inputs = <0x00>;
			phandle = <0x10>;
		};

		gpio@a0300000 {
			xlnx,gpio-board-interface = "Custom";
			compatible = "xlnx,axi-gpio-2.0\0xlnx,xps-gpio-1.00.a";
			xlnx,all-outputs = <0x01>;
			#gpio-cells = <0x02>;
			xlnx,gpio-width = <0x08>;
			xlnx,dout-default = <0xffffffff>;
			xlnx,is-dual = <0x00>;
			xlnx,ip-name = "axi_gpio";
			xlnx,tri-default-2 = <0xffffffff>;
			reg = <0x00 0xa0300000 0x00 0x10000>;
			xlnx,all-inputs-2 = <0x00>;
			clocks = <0x85 0x47>;
			xlnx,all-outputs-2 = <0x00>;
			gpio-controller;
			xlnx,interrupt-present = <0x00>;
			xlnx,gpio2-board-interface = "Custom";
			xlnx,edk-iptype = "PERIPHERAL";
			xlnx,dout-default-2 = <0x00>;
			status = "okay";
			xlnx,gpio2-width = <0x20>;
			clock-names = "s_axi_aclk";
			xlnx,tri-default = <0xffffffff>;
			xlnx,all-inputs = <0x00>;
			phandle = <0x15>;
		};

		gpio@a0205000 {
			xlnx,gpio-board-interface = "Custom";
			compatible = "xlnx,axi-gpio-2.0\0xlnx,xps-gpio-1.00.a";
			xlnx,all-outputs = <0x01>;
			#gpio-cells = <0x02>;
			xlnx,gpio-width = <0x02>;
			xlnx,dout-default = <0x00>;
			xlnx,is-dual = <0x00>;
			xlnx,ip-name = "axi_gpio";
			xlnx,tri-default-2 = <0xffffffff>;
			reg = <0x00 0xa0205000 0x00 0x1000>;
			xlnx,all-inputs-2 = <0x00>;
			clocks = <0x85 0x47>;
			xlnx,all-outputs-2 = <0x00>;
			gpio-controller;
			xlnx,interrupt-present = <0x00>;
			xlnx,gpio2-board-interface = "Custom";
			xlnx,edk-iptype = "PERIPHERAL";
			xlnx,dout-default-2 = <0x00>;
			status = "okay";
			xlnx,gpio2-width = <0x20>;
			clock-names = "s_axi_aclk";
			xlnx,tri-default = <0xffffffff>;
			xlnx,all-inputs = <0x00>;
			phandle = <0x13>;
		};

		exdes_rfadc_data_bram_capture@b0400000 {
			compatible = "xlnx,exdes-rfadc-data-bram-capture-1.0";
			xlnx,edk-special = "MONITOR";
			xlnx,ip-name = "exdes_rfadc_data_bram_capture";
			xlnx,mem-size = <0x40000>;
			reg = <0x00 0xb0400000 0x00 0x200000>;
			clocks = <0xb7 0xb7 0xb7 0xb7 0xb7 0xb7 0xb7 0xb7 0x85 0x47>;
			xlnx,axi-addr-top = <0x13>;
			xlnx,use-div2-clk-0 = <0x00>;
			xlnx,edk-iptype = "MONITOR";
			xlnx,use-div2-clk-1 = <0x00>;
			xlnx,use-div2-clk-2 = <0x00>;
			xlnx,use-div2-clk-3 = <0x00>;
			status = "okay";
			clock-names = "s0_axis_clock\0s0_div2_axis_clock\0s1_axis_clock\0s1_div2_axis_clock\0s2_axis_clock\0s2_div2_axis_clock\0s3_axis_clock\0s3_div2_axis_clock\0s_axi_aclk";
			phandle = <0x19>;
		};

		exdes_rfdac_data_bram_stim@b0000000 {
			compatible = "xlnx,exdes-rfdac-data-bram-stim-1.0";
			xlnx,ip-name = "exdes_rfdac_data_bram_stim";
			xlnx,mem-size = <0x40000>;
			reg = <0x00 0xb0000000 0x00 0x200000>;
			clocks = <0x1b 0x00 0x1b 0x00 0x1c 0x00 0x1c 0x00 0x1d 0x00 0x1d 0x00 0x1e 0x00 0x1e 0x00 0x85 0x47>;
			xlnx,axi-addr-top = <0x13>;
			xlnx,use-div2-clk-0 = <0x00>;
			xlnx,edk-iptype = "PERIPHERAL";
			xlnx,use-div2-clk-1 = <0x00>;
			xlnx,use-div2-clk-2 = <0x00>;
			status = "okay";
			xlnx,use-div2-clk-3 = <0x00>;
			clock-names = "m0_axis_clock\0m0_div2_axis_clock\0m1_axis_clock\0m1_div2_axis_clock\0m2_axis_clock\0m2_div2_axis_clock\0m3_axis_clock\0m3_div2_axis_clock\0s_axi_aclk";
			phandle = <0x17>;
		};

		usp_rf_data_converter@b4b00000 {
			reg = <0x00 0xb4b00000 0x00 0x40000>;
			clock-names = "m0_axis_aclk\0m1_axis_aclk\0m2_axis_aclk\0m3_axis_aclk\0s0_axis_aclk\0s1_axis_aclk\0s2_axis_aclk\0s3_axis_aclk\0s_axi_aclk";
			compatible = "xlnx,usp-rf-data-converter-2.6";
			param-list = <0x00 0xb0b4 0x00 0x00 0x00 0x00 0x1000000 0x1000000 0x2000000 0x1000000 0x1000000 0x1000000 0x691d554d 0x10751f40 0xb81e85eb 0x51b86e40 0xb81e85eb 0x51b86e40 0x20000000 0x1000000 0x1000000 0x00 0x00 0x2440 0x4000000 0x00 0x1000000 0x00 0x00 0x00 0x1000000 0x00 0x00 0x00 0x1000000 0x00 0x00 0x00 0x1000000 0x00 0x00 0x00 0x00 0x10000000 0x2000000 0x00 0x00 0x2000000 0x00 0x00 0x00 0x10000000 0x2000000 0x00 0x00 0x2000000 0x00 0x00 0x00 0x10000000 0x2000000 0x00 0x00 0x2000000 0x00 0x00 0x00 0x10000000 0x2000000 0x00 0x00 0x2000000 0x00 0x00 0x1000000 0x1000000 0x691d554d 0x10751f40 0xb81e85eb 0x51b86e40 0xb81e85eb 0x51b86e40 0x20000000 0x1000000 0x1000000 0x00 0x00 0x2440 0x4000000 0x00 0x1000000 0x00 0x00 0x00 0x1000000 0x00 0x00 0x00 0x1000000 0x00 0x00 0x00 0x1000000 0x00 0x00 0x00 0x00 0x10000000 0x2000000 0x00 0x00 0x2000000 0x00 0x00 0x00 0x10000000 0x2000000 0x00 0x00 0x2000000 0x00 0x00 0x00 0x10000000 0x2000000 0x00 0x00 0x2000000 0x00 0x00 0x00 0x10000000 0x2000000 0x00 0x00 0x2000000 0x00 0x00 0x1000000 0x1000000 0x691d554d 0x10751f40 0xb81e85eb 0x51b86e40 0xb81e85eb 0x51b86e40 0x20000000 0x1000000 0x1000000 0x00 0x00 0x2440 0x4000000 0x00 0x1000000 0x00 0x00 0x00 0x1000000 0x00 0x00 0x00 0x1000000 0x00 0x00 0x00 0x1000000 0x00 0x00 0x00 0x00 0x10000000 0x2000000 0x00 0x00 0x2000000 0x00 0x00 0x00 0x10000000 0x2000000 0x00 0x00 0x2000000 0x00 0x00 0x00 0x10000000 0x2000000 0x00 0x00 0x2000000 0x00 0x00 0x00 0x10000000 0x2000000 0x00 0x00 0x2000000 0x00 0x00 0x1000000 0x1000000 0x691d554d 0x10751f40 0xb81e85eb 0x51b86e40 0xb81e85eb 0x51b86e40 0x20000000 0x1000000 0x1000000 0x00 0x00 0x2440 0x4000000 0x00 0x1000000 0x00 0x00 0x00 0x1000000 0x00 0x00 0x00 0x1000000 0x00 0x00 0x00 0x1000000 0x00 0x00 0x00 0x00 0x10000000 0x2000000 0x00 0x00 0x2000000 0x00 0x00 0x00 0x10000000 0x2000000 0x00 0x00 0x2000000 0x00 0x00 0x00 0x10000000 0x2000000 0x00 0x00 0x2000000 0x00 0x00 0x00 0x10000000 0x2000000 0x00 0x00 0x2000000 0x00 0x00 0x1000000 0x1000000 0x8be07f2b 0xd9b10140 0xb81e85eb 0x51b86e40 0xad7a370 0x3d0a7740 0x24000000 0x4000000 0x1000000 0x00 0x00 0x440 0x4000000 0x1000000 0x00 0x1000000 0x00 0x1000000 0x00 0x1000000 0x00 0x1000000 0xc000000 0x1000000 0x00 0x2000000 0x00 0x00 0x1000000 0xc000000 0x1000000 0x00 0x2000000 0x00 0x00 0x1000000 0xc000000 0x1000000 0x00 0x2000000 0x00 0x00 0x1000000 0xc000000 0x1000000 0x00 0x2000000 0x00 0x00 0x1000000 0x1000000 0x8be07f2b 0xd9b10140 0xb81e85eb 0x51b86e40 0xad7a370 0x3d0a7740 0x24000000 0x4000000 0x1000000 0x00 0x00 0x440 0x4000000 0x1000000 0x00 0x1000000 0x00 0x1000000 0x00 0x1000000 0x00 0x1000000 0xc000000 0x1000000 0x00 0x2000000 0x00 0x00 0x1000000 0xc000000 0x1000000 0x00 0x2000000 0x00 0x00 0x1000000 0xc000000 0x1000000 0x00 0x2000000 0x00 0x00 0x1000000 0xc000000 0x1000000 0x00 0x2000000 0x00 0x00 0x1000000 0x1000000 0x8be07f2b 0xd9b10140 0xb81e85eb 0x51b86e40 0xad7a370 0x3d0a7740 0x24000000 0x4000000 0x1000000 0x00 0x00 0x440 0x4000000 0x1000000 0x00 0x1000000 0x00 0x1000000 0x00 0x1000000 0x00 0x1000000 0xc000000 0x1000000 0x00 0x2000000 0x00 0x00 0x1000000 0xc000000 0x1000000 0x00 0x2000000 0x00 0x00 0x1000000 0xc000000 0x1000000 0x00 0x2000000 0x00 0x00 0x1000000 0xc000000 0x1000000 0x00 0x2000000 0x00 0x00 0x1000000 0x1000000 0x8be07f2b 0xd9b10140 0xb81e85eb 0x51b86e40 0xad7a370 0x3d0a7740 0x24000000 0x4000000 0x1000000 0x00 0x00 0x440 0x4000000 0x1000000 0x00 0x1000000 0x00 0x1000000 0x00 0x1000000 0x00 0x1000000 0xc000000 0x1000000 0x00 0x2000000 0x00 0x00 0x1000000 0xc000000 0x1000000 0x00 0x2000000 0x00 0x00 0x1000000 0xc000000 0x1000000 0x00 0x2000000 0x00 0x00 0x1000000 0xc000000 0x1000000 0x00 0x2000000 0x00 0x00>;
			interrupt-names = "irq";
			num-insts = <0x01>;
			interrupt-parent = <0x23>;
			clocks = <0xb7 0xb7 0xb7 0xb7 0x1b 0x00 0x1c 0x00 0x1d 0x00 0x1e 0x00 0x85 0x47>;
			interrupts = <0x00 0x59 0x01>;
			phandle = <0x1a>;
		};

		exdes_tddrtsctrl@b0200000 {
			xlnx,count-width = <0x13>;
			compatible = "xlnx,exdes-tddrtsctrl-1.0";
			status = "okay";
			clock-names = "adc0_clk\0adc1_clk\0adc2_clk\0adc3_clk\0dac0_clk\0dac1_clk\0dac2_clk\0dac3_clk\0s_axi_aclk";
			xlnx,ip-name = "exdes_tddrtsctrl";
			xlnx,edk-iptype = "PERIPHERAL";
			reg = <0x00 0xb0200000 0x00 0x10000>;
			clocks = <0xb7 0xb7 0xb7 0xb7 0x1b 0x00 0x1c 0x00 0x1d 0x00 0x1e 0x00 0x85 0x47>;
			phandle = <0x18>;
		};
	};

	memory@0 {
		compatible = "xlnx,psu-ddr-1.0";
		xlnx,ip-name = "psu_ddr";
		device_type = "memory";
		memory_type = "memory";
		reg = <0x00 0x00 0x00 0x7ff00000>;
		phandle = <0x0d>;
	};

	memory@800000000 {
		compatible = "xlnx,psu-ddr-1.0";
		xlnx,ip-name = "psu_ddr";
		device_type = "memory";
		memory_type = "memory";
		reg = <0x08 0x00 0x00 0x80000000>;
		phandle = <0x0e>;
	};

	chosen {
		bootargs = "earlycon console=ttyPS0,115200 root=/dev/ram0 rw init_fatal_sh=1";
		stdout-path = "serial0:115200n8";
	};

	aliases {
		serial0 = "/axi/serial@ff000000";
		spi0 = "/axi/spi@ff0f0000";
		serial1 = "/dcc";
		i2c0 = "/axi/i2c@ff020000";
		i2c1 = "/axi/i2c@ff030000";
		ethernet0 = "/axi/ethernet@ff0e0000";
		mmc0 = "/axi/mmc@ff170000";
		nvmem0 = "/axi/i2c@ff030000/i2c-mux@74/i2c@0/eeprom@54";
		rtc0 = "/axi/rtc@ffa60000";
		usb0 = "/axi/usb@ff9d0000";
	};

	gpio-keys {
		compatible = "gpio-keys";
		autorepeat;

		switch-19 {
			label = "sw19";
			gpios = <0x59 0x16 0x00>;
			linux,code = <0x6c>;
			wakeup-source;
			autorepeat;
		};
	};

	leds {
		compatible = "gpio-leds";

		heartbeat-led {
			label = "heartbeat";
			gpios = <0x59 0x17 0x00>;
			linux,default-trigger = "heartbeat";
		};
	};

	ina226-vccint {
		compatible = "iio-hwmon";
		io-channels = <0xb9 0x00 0xb9 0x01 0xb9 0x02 0xb9 0x03>;
	};

	ina226-vccint-io-bram-ps {
		compatible = "iio-hwmon";
		io-channels = <0xba 0x00 0xba 0x01 0xba 0x02 0xba 0x03>;
	};

	ina226-vcc1v8 {
		compatible = "iio-hwmon";
		io-channels = <0xbb 0x00 0xbb 0x01 0xbb 0x02 0xbb 0x03>;
	};

	ina226-vcc1v2 {
		compatible = "iio-hwmon";
		io-channels = <0xbc 0x00 0xbc 0x01 0xbc 0x02 0xbc 0x03>;
	};

	ina226-vadj-fmc {
		compatible = "iio-hwmon";
		io-channels = <0xbd 0x00 0xbd 0x01 0xbd 0x02 0xbd 0x03>;
	};

	ina226-mgtavcc {
		compatible = "iio-hwmon";
		io-channels = <0xbe 0x00 0xbe 0x01 0xbe 0x02 0xbe 0x03>;
	};

	ina226-mgt1v2 {
		compatible = "iio-hwmon";
		io-channels = <0xbf 0x00 0xbf 0x01 0xbf 0x02 0xbf 0x03>;
	};

	ina226-mgt1v8 {
		compatible = "iio-hwmon";
		io-channels = <0xc0 0x00 0xc0 0x01 0xc0 0x02 0xc0 0x03>;
	};

	ina226-vccint-ams {
		compatible = "iio-hwmon";
		io-channels = <0xc1 0x00 0xc1 0x01 0xc1 0x02 0xc1 0x03>;
	};

	ina226-dac-avtt {
		compatible = "iio-hwmon";
		io-channels = <0xc2 0x00 0xc2 0x01 0xc2 0x02 0xc2 0x03>;
	};

	ina226-dac-avccaux {
		compatible = "iio-hwmon";
		io-channels = <0xc3 0x00 0xc3 0x01 0xc3 0x02 0xc3 0x03>;
	};

	ina226-adc-avcc {
		compatible = "iio-hwmon";
		io-channels = <0xc4 0x00 0xc4 0x01 0xc4 0x02 0xc4 0x03>;
	};

	ina226-adc-avccaux {
		compatible = "iio-hwmon";
		io-channels = <0xc5 0x00 0xc5 0x01 0xc5 0x02 0xc5 0x03>;
	};

	ina226-dac-avcc {
		compatible = "iio-hwmon";
		io-channels = <0xc6 0x00 0xc6 0x01 0xc6 0x02 0xc6 0x03>;
	};

	ref48M {
		compatible = "fixed-clock";
		#clock-cells = <0x00>;
		clock-frequency = <0x2dc6c00>;
		phandle = <0xaf>;
	};

	__symbols__ {
		cpus_a53 = "/cpus-a53@0";
		psu_cortexa53_0 = "/cpus-a53@0/cpu@0";
		psu_cortexa53_1 = "/cpus-a53@0/cpu@1";
		psu_cortexa53_2 = "/cpus-a53@0/cpu@2";
		psu_cortexa53_3 = "/cpus-a53@0/cpu@3";
		L2 = "/cpus-a53@0/l2-cache";
		CPU_SLEEP_0 = "/cpus-a53@0/idle-states/cpu-sleep-0";
		cpu_opp_table = "/opp-table-cpu";
		zynqmp_ipi = "/zynqmp-ipi";
		ipi_mailbox_pmu1 = "/zynqmp-ipi/mailbox@ff9905c0";
		dcc = "/dcc";
		zynqmp_firmware = "/firmware/zynqmp-firmware";
		zynqmp_power = "/firmware/zynqmp-firmware/power-management";
		soc_revision = "/firmware/zynqmp-firmware/soc-nvmem/nvmem-layout/soc-revision@0";
		efuse_dna = "/firmware/zynqmp-firmware/soc-nvmem/nvmem-layout/efuse-dna@c";
		efuse_usr0 = "/firmware/zynqmp-firmware/soc-nvmem/nvmem-layout/efuse-usr0@20";
		efuse_usr1 = "/firmware/zynqmp-firmware/soc-nvmem/nvmem-layout/efuse-usr1@24";
		efuse_usr2 = "/firmware/zynqmp-firmware/soc-nvmem/nvmem-layout/efuse-usr2@28";
		efuse_usr3 = "/firmware/zynqmp-firmware/soc-nvmem/nvmem-layout/efuse-usr3@2c";
		efuse_usr4 = "/firmware/zynqmp-firmware/soc-nvmem/nvmem-layout/efuse-usr4@30";
		efuse_usr5 = "/firmware/zynqmp-firmware/soc-nvmem/nvmem-layout/efuse-usr5@34";
		efuse_usr6 = "/firmware/zynqmp-firmware/soc-nvmem/nvmem-layout/efuse-usr6@38";
		efuse_usr7 = "/firmware/zynqmp-firmware/soc-nvmem/nvmem-layout/efuse-usr7@3c";
		efuse_miscusr = "/firmware/zynqmp-firmware/soc-nvmem/nvmem-layout/efuse-miscusr@40";
		efuse_chash = "/firmware/zynqmp-firmware/soc-nvmem/nvmem-layout/efuse-chash@50";
		efuse_pufmisc = "/firmware/zynqmp-firmware/soc-nvmem/nvmem-layout/efuse-pufmisc@54";
		efuse_sec = "/firmware/zynqmp-firmware/soc-nvmem/nvmem-layout/efuse-sec@58";
		efuse_spkid = "/firmware/zynqmp-firmware/soc-nvmem/nvmem-layout/efuse-spkid@5c";
		efuse_aeskey = "/firmware/zynqmp-firmware/soc-nvmem/nvmem-layout/efuse-aeskey@60";
		efuse_ppk0hash = "/firmware/zynqmp-firmware/soc-nvmem/nvmem-layout/efuse-ppk0hash@a0";
		efuse_ppk1hash = "/firmware/zynqmp-firmware/soc-nvmem/nvmem-layout/efuse-ppk1hash@d0";
		efuse_pufuser = "/firmware/zynqmp-firmware/soc-nvmem/nvmem-layout/efuse-pufuser@100";
		zynqmp_pcap = "/firmware/zynqmp-firmware/pcap";
		zynqmp_reset = "/firmware/zynqmp-firmware/reset-controller";
		pinctrl0 = "/firmware/zynqmp-firmware/pinctrl";
		pinctrl_i2c0_default = "/firmware/zynqmp-firmware/pinctrl/i2c0-default";
		pinctrl_i2c0_gpio = "/firmware/zynqmp-firmware/pinctrl/i2c0-gpio-grp";
		pinctrl_i2c1_default = "/firmware/zynqmp-firmware/pinctrl/i2c1-default";
		pinctrl_i2c1_gpio = "/firmware/zynqmp-firmware/pinctrl/i2c1-gpio-grp";
		modepin_gpio = "/firmware/zynqmp-firmware/gpio";
		zynqmp_clk = "/firmware/zynqmp-firmware/clock-controller";
		fpga_full = "/fpga-region";
		tsens_apu = "/thermal-sensor-apu";
		tsens_rpu = "/thermal-sensor-rpu";
		tsens_pl = "/thermal-sensor-pl";
		apu_passive = "/thermal-zones/apu-thermal/trips/passive";
		apu_critical = "/thermal-zones/apu-thermal/trips/critical";
		amba_apu = "/apu-bus";
		amba = "/axi";
		imux = "/axi/interrupt-multiplex";
		can0 = "/axi/can@ff060000";
		can1 = "/axi/can@ff070000";
		cci = "/axi/cci@fd6e0000";
		psu_cortexa53_0_debug = "/axi/debug@fec10000";
		psu_cortexa53_1_debug = "/axi/debug@fed10000";
		psu_cortexa53_2_debug = "/axi/debug@fee10000";
		psu_cortexa53_3_debug = "/axi/debug@fef10000";
		fpd_dma_chan1 = "/axi/dma-controller@fd500000";
		fpd_dma_chan2 = "/axi/dma-controller@fd510000";
		fpd_dma_chan3 = "/axi/dma-controller@fd520000";
		fpd_dma_chan4 = "/axi/dma-controller@fd530000";
		fpd_dma_chan5 = "/axi/dma-controller@fd540000";
		fpd_dma_chan6 = "/axi/dma-controller@fd550000";
		fpd_dma_chan7 = "/axi/dma-controller@fd560000";
		fpd_dma_chan8 = "/axi/dma-controller@fd570000";
		gpu = "/axi/gpu@fd4b0000";
		lpd_dma_chan1 = "/axi/dma-controller@ffa80000";
		lpd_dma_chan2 = "/axi/dma-controller@ffa90000";
		lpd_dma_chan3 = "/axi/dma-controller@ffaa0000";
		lpd_dma_chan4 = "/axi/dma-controller@ffab0000";
		lpd_dma_chan5 = "/axi/dma-controller@ffac0000";
		lpd_dma_chan6 = "/axi/dma-controller@ffad0000";
		lpd_dma_chan7 = "/axi/dma-controller@ffae0000";
		lpd_dma_chan8 = "/axi/dma-controller@ffaf0000";
		mc = "/axi/memory-controller@fd070000";
		nand0 = "/axi/nand-controller@ff100000";
		gem0 = "/axi/ethernet@ff0b0000";
		gem1 = "/axi/ethernet@ff0c0000";
		gem2 = "/axi/ethernet@ff0d0000";
		gem3 = "/axi/ethernet@ff0e0000";
		mdio = "/axi/ethernet@ff0e0000/mdio";
		phy0 = "/axi/ethernet@ff0e0000/mdio/ethernet-phy@c";
		gpio = "/axi/gpio@ff0a0000";
		i2c0 = "/axi/i2c@ff020000";
		tca6416_u15 = "/axi/i2c@ff020000/gpio@20";
		vccint = "/axi/i2c@ff020000/i2c-mux@75/i2c@0/ina226@40";
		vccint_io_bram_ps = "/axi/i2c@ff020000/i2c-mux@75/i2c@0/ina226@41";
		vcc1v8 = "/axi/i2c@ff020000/i2c-mux@75/i2c@0/ina226@42";
		vcc1v2 = "/axi/i2c@ff020000/i2c-mux@75/i2c@0/ina226@43";
		vadj_fmc = "/axi/i2c@ff020000/i2c-mux@75/i2c@0/ina226@45";
		mgtavcc = "/axi/i2c@ff020000/i2c-mux@75/i2c@0/ina226@46";
		mgt1v2 = "/axi/i2c@ff020000/i2c-mux@75/i2c@0/ina226@47";
		mgt1v8 = "/axi/i2c@ff020000/i2c-mux@75/i2c@0/ina226@48";
		vccint_ams = "/axi/i2c@ff020000/i2c-mux@75/i2c@0/ina226@49";
		dac_avtt = "/axi/i2c@ff020000/i2c-mux@75/i2c@0/ina226@4a";
		dac_avccaux = "/axi/i2c@ff020000/i2c-mux@75/i2c@0/ina226@4b";
		adc_avcc = "/axi/i2c@ff020000/i2c-mux@75/i2c@0/ina226@4c";
		adc_avccaux = "/axi/i2c@ff020000/i2c-mux@75/i2c@0/ina226@4d";
		dac_avcc = "/axi/i2c@ff020000/i2c-mux@75/i2c@0/ina226@4e";
		irps5401_44 = "/axi/i2c@ff020000/i2c-mux@75/i2c@2/irps5401@44";
		irps5401_45 = "/axi/i2c@ff020000/i2c-mux@75/i2c@2/irps5401@45";
		i2c1 = "/axi/i2c@ff030000";
		i2c_eeprom = "/axi/i2c@ff030000/i2c-mux@74/i2c@0";
		eeprom = "/axi/i2c@ff030000/i2c-mux@74/i2c@0/eeprom@54";
		i2c_si5341 = "/axi/i2c@ff030000/i2c-mux@74/i2c@1";
		si5341 = "/axi/i2c@ff030000/i2c-mux@74/i2c@1/clock-generator@36";
		si5341_2 = "/axi/i2c@ff030000/i2c-mux@74/i2c@1/clock-generator@36/out@2";
		si5341_3 = "/axi/i2c@ff030000/i2c-mux@74/i2c@1/clock-generator@36/out@3";
		si5341_5 = "/axi/i2c@ff030000/i2c-mux@74/i2c@1/clock-generator@36/out@5";
		si5341_6 = "/axi/i2c@ff030000/i2c-mux@74/i2c@1/clock-generator@36/out@6";
		si5341_9 = "/axi/i2c@ff030000/i2c-mux@74/i2c@1/clock-generator@36/out@9";
		i2c_si570_user_c0 = "/axi/i2c@ff030000/i2c-mux@74/i2c@2";
		si570_1 = "/axi/i2c@ff030000/i2c-mux@74/i2c@2/clock-generator@5d";
		i2c_si570_mgt = "/axi/i2c@ff030000/i2c-mux@74/i2c@3";
		si570_2 = "/axi/i2c@ff030000/i2c-mux@74/i2c@3/clock-generator@5d";
		i2c_8a34001 = "/axi/i2c@ff030000/i2c-mux@74/i2c@4";
		idt_8a34001 = "/axi/i2c@ff030000/i2c-mux@74/i2c@4/phc@5b";
		i2c_clk104 = "/axi/i2c@ff030000/i2c-mux@74/i2c@5";
		i2c_si570_user_c1 = "/axi/i2c@ff030000/i2c-mux@75/i2c@1";
		si570_3 = "/axi/i2c@ff030000/i2c-mux@75/i2c@1/clock-generator@5d";
		ocm = "/axi/memory-controller@ff960000";
		perf_monitor_ocm = "/axi/perf-monitor@ffa00000";
		perf_monitor_ddr = "/axi/perf-monitor@fd0b0000";
		perf_monitor_cci = "/axi/perf-monitor@fd490000";
		perf_monitor_lpd = "/axi/perf-monitor@ffa10000";
		pcie = "/axi/pcie@fd0e0000";
		pcie_intc = "/axi/pcie@fd0e0000/legacy-interrupt-controller";
		qspi = "/axi/spi@ff0f0000";
		psgtr = "/axi/phy@fd400000";
		rtc = "/axi/rtc@ffa60000";
		sata = "/axi/ahci@fd0c0000";
		sdhci0 = "/axi/mmc@ff160000";
		sdhci1 = "/axi/mmc@ff170000";
		smmu = "/axi/iommu@fd800000";
		spi0 = "/axi/spi@ff040000";
		spi1 = "/axi/spi@ff050000";
		uart0 = "/axi/serial@ff000000";
		uart1 = "/axi/serial@ff010000";
		usb0 = "/axi/usb@ff9d0000";
		dwc3_0 = "/axi/usb@ff9d0000/usb@fe200000";
		usb1 = "/axi/usb@ff9e0000";
		dwc3_1 = "/axi/usb@ff9e0000/usb@fe300000";
		watchdog0 = "/axi/watchdog@fd4d0000";
		lpd_watchdog = "/axi/watchdog@ff150000";
		xilinx_ams = "/axi/ams@ffa50000";
		ams_ps = "/axi/ams@ffa50000/ams-ps@0";
		ams_pl = "/axi/ams@ffa50000/ams-pl@400";
		zynqmp_dpdma = "/axi/dma-controller@fd4c0000";
		zynqmp_dpsub = "/axi/display@fd4a0000";
		live_video = "/axi/display@fd4a0000/ports/port@0";
		live_gfx = "/axi/display@fd4a0000/ports/port@1";
		live_audio = "/axi/display@fd4a0000/ports/port@2";
		out_video = "/axi/display@fd4a0000/ports/port@3";
		out_audio = "/axi/display@fd4a0000/ports/port@4";
		out_dp = "/axi/display@fd4a0000/ports/port@5";
		coresight_0 = "/axi/coresight@fe800000";
		csudma_0 = "/axi/dma@ffc80000";
		ipi9 = "/axi/ipi@ff360000";
		ipi10 = "/axi/ipi@ff370000";
		psu_csu_0 = "/axi/psu_csu@ffca0000";
		psu_smmu_reg = "/axi/psu_smmu_reg@fd5f0000";
		psu_cci_reg = "/axi/psu_cci_reg@fd5e0000";
		psu_afi_5 = "/axi/psu_afi@fd3b0000";
		psu_afi_4 = "/axi/psu_afi@fd3a0000";
		psu_afi_3 = "/axi/psu_afi@fd390000";
		psu_afi_2 = "/axi/psu_afi@fd380000";
		psu_afi_1 = "/axi/psu_afi@fd370000";
		psu_afi_0 = "/axi/psu_afi@fd360000";
		psu_afi_6 = "/axi/psu_afi@ff9b0000";
		psu_ctrl_ipi = "/axi/PERIPHERAL@ff380000";
		psu_message_buffers = "/axi/PERIPHERAL@ff990000";
		psu_iouslcr_0 = "/axi/psu_iouslcr@ff180000";
		psu_qspi_linear_0 = "/axi/psu_qspi_linear@c0000000";
		amba_xppu = "/indirect-bus@1";
		lpd_xppu = "/indirect-bus@1/xppu@ff980000";
		binman = "/binman";
		pss_ref_clk = "/pss-ref-clk";
		video_clk = "/video-clk";
		pss_alt_ref_clk = "/pss-alt-ref-clk";
		gt_crx_ref_clk = "/gt-crx-ref-clk";
		aux_ref_clk = "/aux-ref-clk";
		amba_pl = "/amba_pl";
		clocking_block_clk_wiz_dac3 = "/amba_pl/clk_wiz@b4c30000";
		clocking_block_clk_wiz_dac2 = "/amba_pl/clk_wiz@b4c20000";
		clocking_block_clk_wiz_dac1 = "/amba_pl/clk_wiz@b4c10000";
		clocking_block_clk_wiz_dac0 = "/amba_pl/clk_wiz@b4c00000";
		clocking_block_clk_wiz_adc3 = "/amba_pl/clk_wiz@b4c70000";
		clocking_block_clk_wiz_adc2 = "/amba_pl/clk_wiz@b4c60000";
		clocking_block_clk_wiz_adc1 = "/amba_pl/clk_wiz@b4c50000";
		clocking_block_clk_wiz_adc0 = "/amba_pl/clk_wiz@b4c40000";
		misc_clk_1 = "/amba_pl/misc_clk_1";
		misc_clk_3 = "/amba_pl/misc_clk_3";
		misc_clk_2 = "/amba_pl/misc_clk_2";
		misc_clk_0 = "/amba_pl/misc_clk_0";
		ADC_DDR_DMA_axi_dma_0 = "/amba_pl/dma@a0203000";
		dma_channel_a0203030 = "/amba_pl/dma@a0203000/dma-channel@a0203030";
		ADC_DDR_DMA_axis_inter_adc_xbar = "/amba_pl/axis_switch@a0204000";
		ADC_DDR_DMA_tlast_gen_v1_0_0 = "/amba_pl/tlast_gen_v1_0@a0310000";
		DAC_DDR_DMA_axi_dma_0 = "/amba_pl/dma@a0000000";
		dma_channel_a0000000 = "/amba_pl/dma@a0000000/dma-channel@a0000000";
		PS_Subsystem_axi_gpio_adc = "/amba_pl/gpio@a0240000";
		PS_Subsystem_axi_gpio_dac = "/amba_pl/gpio@a0202000";
		PS_Subsystem_axi_gpio_mts = "/amba_pl/gpio@a0300000";
		PS_Subsystem_axi_gpio_spi_mux = "/amba_pl/gpio@a0205000";
		ex_design_adc_sink_i = "/amba_pl/exdes_rfadc_data_bram_capture@b0400000";
		ex_design_dac_source_i = "/amba_pl/exdes_rfdac_data_bram_stim@b0000000";
		ex_design_rfip = "/amba_pl/usp_rf_data_converter@b4b00000";
		ex_design_tdd_module_i = "/amba_pl/exdes_tddrtsctrl@b0200000";
		psu_ddr_0_memory = "/memory@0";
		psu_ddr_1_memory = "/memory@800000000";
		ref48 = "/ref48M";
		gic = "/axi/interrupt-controller@f9010000";
		flash0 = "/axi/spi@ff0f0000/flash@0";
	};

	domains {

		openamp_a53_0_cluster {
			compatible = "openamp,domain-v1";
			cpus = <0xc7 0x01 0x80000003>;
			phandle = <0x17e>;

			reserved-memory {
				ranges = <0x01>;

				rpu0vdev0vring1 {
					start = <0x9864000>;
					size = <0x4000>;
					no-map = <0x01>;
					phandle = <0x179>;
				};

				rpu0vdev0vring0 {
					start = <0x9860000>;
					size = <0x4000>;
					no-map = <0x01>;
					phandle = <0x178>;
				};

				rpu0vdev0buffer {
					start = <0x9868000>;
					size = <0x40000>;
					no-map = <0x01>;
					phandle = <0x17a>;
				};

				rproc0 {
					start = <0x9800000>;
					size = <0x60000>;
					no-map = <0x01>;
					phandle = <0x176>;
				};

				rpu1vdev0vring1 {
					start = <0x9e64000>;
					size = <0x4000>;
					no-map = <0x01>;
					phandle = <0x17c>;
				};

				rpu1vdev0vring0 {
					start = <0x9e60000>;
					size = <0x4000>;
					no-map = <0x01>;
					phandle = <0x17b>;
				};

				rpu1vdev0buffer {
					start = <0x9e68000>;
					size = <0x40000>;
					no-map = <0x01>;
					phandle = <0x17d>;
				};

				rproc1 {
					start = <0x9e00000>;
					size = <0x60000>;
					no-map = <0x01>;
					phandle = <0x177>;
				};
			};

			domain-to-domain {
				compatible = "openamp,domain-to-domain-v1";

				remoteproc-relation {
					compatible = "openamp,remoteproc-v2";
					remote = <0x174 0x175>;
					elfload;
					elfload0 = <0x6b 0x6c 0x176>;
					elfload1 = <0x6d 0x6e 0x177>;
				};

				rpmsg-relation {
					compatible = "openamp,rpmsg-v1";
					openamp-xlnx-native = <0x00 0x00>;
					remote = <0x174 0x175>;
					carveouts = <0x178 0x179 0x17a 0x17b 0x17c 0x17d>;
					mbox = <0x0b 0x0b>;
				};
			};

			access {
				dev = "psu_r5_0_btcm_global";
				flags = <0x00>;
			};
		};

		openamp_r5_1_cluster {
			compatible = "openamp,domain-v1";
			phandle = <0x175>;

			reserved-memory {
				ranges = <0x01>;

				rpu1vdev0vring1 {
					start = <0x9e64000>;
					size = <0x4000>;
					no-map = <0x01>;
					phandle = <0x180>;
				};

				rpu1vdev0vring0 {
					start = <0x9e60000>;
					size = <0x4000>;
					no-map = <0x01>;
					phandle = <0x17f>;
				};

				rpu1vdev0buffer {
					start = <0x9e68000>;
					size = <0x40000>;
					no-map = <0x01>;
					phandle = <0x181>;
				};

				rproc1 {
					start = <0x9e00000>;
					size = <0x60000>;
					no-map = <0x01>;
				};
			};

			domain-to-domain {
				compatible = "openamp,domain-to-domain-v1";

				rpmsg-relation {
					compatible = "openamp,rpmsg-v1";
					host = <0x17e>;
					mbox = <0x8f>;
					carveouts = <0x17f 0x180 0x181>;
				};
			};

			access {
				dev = "psu_r5_1_btcm_global";
				flags = <0x00>;
			};
		};

		openamp_r5_0_cluster {
			compatible = "openamp,domain-v1";
			phandle = <0x174>;

			reserved-memory {
				ranges = <0x01>;

				rpu0vdev0vring1 {
					start = <0x9864000>;
					size = <0x4000>;
					no-map = <0x01>;
					phandle = <0x183>;
				};

				rpu0vdev0vring0 {
					start = <0x9860000>;
					size = <0x4000>;
					no-map = <0x01>;
					phandle = <0x182>;
				};

				rpu0vdev0buffer {
					start = <0x9868000>;
					size = <0x40000>;
					no-map = <0x01>;
					phandle = <0x184>;
				};

				rproc0 {
					start = <0x9800000>;
					size = <0x60000>;
					no-map = <0x01>;
				};
			};

			domain-to-domain {
				compatible = "openamp,domain-to-domain-v1";

				rpmsg-relation {
					compatible = "openamp,rpmsg-v1";
					host = <0x17e>;
					mbox = <0x87>;
					carveouts = <0x182 0x183 0x184>;
				};
			};

			access {
				dev = "psu_r5_0_btcm_global";
				flags = <0x00>;
			};
		};
	};

	reserved-memory {
		#address-cells = <0x02>;
		#size-cells = <0x02>;
		ranges;

		rproc0 {
			no-map;
			reg = <0x00 0x9800000 0x00 0x60000>;
			phandle = <0x185>;
		};

		rproc1 {
			no-map;
			reg = <0x00 0x9e00000 0x00 0x60000>;
			phandle = <0x186>;
		};

		vdev0vring0@9860000 {
			no-map;
			reg = <0x00 0x9860000 0x00 0x4000>;
			phandle = <0x187>;
		};

		vdev0vring1@9864000 {
			no-map;
			reg = <0x00 0x9864000 0x00 0x4000>;
			phandle = <0x188>;
		};

		vdev0buffer@9868000 {
			no-map;
			reg = <0x00 0x9868000 0x00 0x40000>;
			compatible = "shared-dma-pool";
			phandle = <0x189>;
		};

		vdev0vring0@9e60000 {
			no-map;
			reg = <0x00 0x9e60000 0x00 0x4000>;
			phandle = <0x18c>;
		};

		vdev0vring1@9e64000 {
			no-map;
			reg = <0x00 0x9e64000 0x00 0x4000>;
			phandle = <0x18d>;
		};

		vdev0buffer@9e68000 {
			no-map;
			reg = <0x00 0x9e68000 0x00 0x40000>;
			compatible = "shared-dma-pool";
			phandle = <0x18e>;
		};
	};

	remoteproc@ffe00000 {
		compatible = "xlnx,zynqmp-r5fss";
		xlnx,cluster-mode = <0x00>;
		xlnx,tcm-mode = <0x00>;
		#address-cells = <0x02>;
		#size-cells = <0x02>;
		ranges = <0x00 0x00 0x00 0xffe00000 0x00 0x10000 0x00 0x20000 0x00 0xffe20000 0x00 0x10000 0x01 0x00 0x00 0xffe90000 0x00 0x10000 0x01 0x20000 0x00 0xffeb0000 0x00 0x10000>;

		r5f@0 {
			compatible = "xlnx,zynqmp-r5f";
			reg-names = "atcm0\0btcm0";
			reg = <0x00 0x00 0x00 0x10000 0x00 0x20000 0x00 0x10000>;
			memory-region = <0x185 0x189 0x187 0x188>;
			power-domains = <0x8e 0x07 0x8e 0x0f 0x8e 0x10>;
			mboxes = <0x18b 0x00 0x18b 0x01>;
			mbox-names = "tx\0rx";
		};

		r5f@1 {
			compatible = "xlnx,zynqmp-r5f";
			reg-names = "atcm0\0btcm0";
			reg = <0x01 0x00 0x00 0x10000 0x01 0x20000 0x00 0x10000>;
			memory-region = <0x186 0x18e 0x18c 0x18d>;
			power-domains = <0x8e 0x08 0x8e 0x11 0x8e 0x12>;
			mboxes = <0x18f 0x00 0x18f 0x01>;
			mbox-names = "tx\0rx";
		};
	};

	zynqmp_ipi1 {
		compatible = "xlnx,zynqmp-ipi-mailbox";
		interrupt-parent = <0x23>;
		#address-cells = <0x01>;
		#size-cells = <0x01>;
		ranges;
		interrupts = <0x00 0x1d 0x04>;
		xlnx,ipi-id = <0x07>;
		phandle = <0x18a>;

		ipi_mailbox_rpu0 {
			phandle = <0x18b>;
			#mbox-cells = <0x01>;
			compatible = "xlnx,zynqmp-ipi-dest-mailbox";
			xlnx,ipi-id = <0x01>;
			reg-names = "local_request_region\0local_response_region\0remote_request_region\0remote_response_region";
			reg = <0xff990600 0x20 0xff990620 0x20 0xff9900c0 0x20 0xff9900e0 0x20>;
		};

		ipi_mailbox_rpu1 {
			phandle = <0x18f>;
			#mbox-cells = <0x01>;
			compatible = "xlnx,zynqmp-ipi-dest-mailbox";
			xlnx,ipi-id = <0x02>;
			reg-names = "local_request_region\0local_response_region\0remote_request_region\0remote_response_region";
			reg = <0xff990640 0x20 0xff990660 0x20 0xff9902c0 0x20 0xff9902e0 0x20>;
		};
	};
};
